VERSION "created by canmatrix"

NS_ :

BS_:

BU_: DMSCCfg

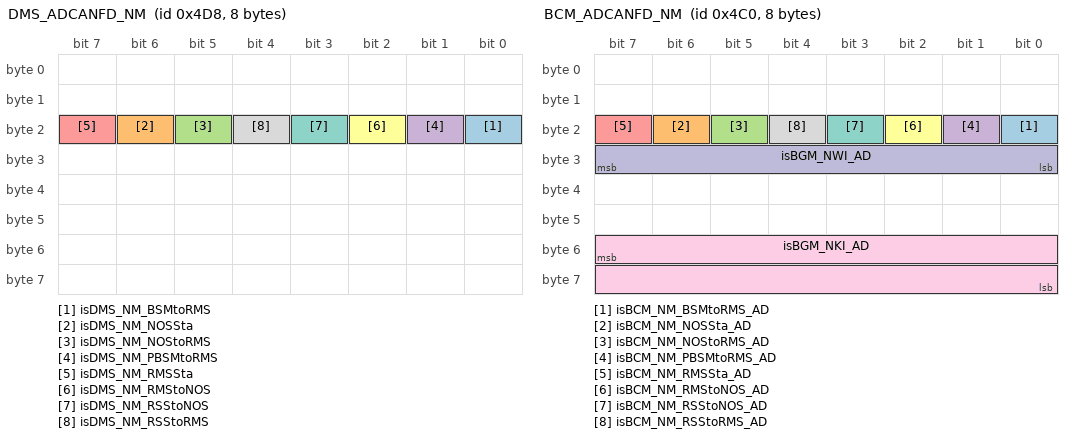
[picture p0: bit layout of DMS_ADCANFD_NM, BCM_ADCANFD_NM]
BO_ 1240 DMS_ADCANFD_NM: 8 DMSCCfg
 SG_ isDMS_NM_BSMtoRMS : 16|1@0+ (1,0) [0|1] "" Vector__XXX
 SG_ isDMS_NM_NOSSta : 22|1@0+ (1,0) [0|1] "" Vector__XXX
 SG_ isDMS_NM_NOStoRMS : 21|1@0+ (1,0) [0|1] "" Vector__XXX
 SG_ isDMS_NM_PBSMtoRMS : 17|1@0+ (1,0) [0|1] "" Vector__XXX
 SG_ isDMS_NM_RMSSta : 23|1@0+ (1,0) [0|1] "" Vector__XXX
 SG_ isDMS_NM_RMStoNOS : 18|1@0+ (1,0) [0|1] "" Vector__XXX
 SG_ isDMS_NM_RSStoNOS : 19|1@0+ (1,0) [0|1] "" Vector__XXX
 SG_ isDMS_NM_RSStoRMS : 20|1@0+ (1,0) [0|1] "" Vector__XXX

BO_ 1994 DIAG_ADCANFD_DTCInfo_DMS: 7 DMSCCfg
 SG_ isDTCInfomationDMS : 7|56@0+ (1,0) [0|7.20575940379279E+016] "" Vector__XXX

BO_ 1216 BCM_ADCANFD_NM: 8 Vector__XXX
 SG_ isBCM_NM_BSMtoRMS_AD : 16|1@0+ (1,0) [0|1] "" Vector__XXX
 SG_ isBCM_NM_NOSSta_AD : 22|1@0+ (1,0) [0|1] "" Vector__XXX
 SG_ isBCM_NM_NOStoRMS_AD : 21|1@0+ (1,0) [0|1] "" Vector__XXX
 SG_ isBCM_NM_PBSMtoRMS_AD : 17|1@0+ (1,0) [0|1] "" Vector__XXX
 SG_ isBCM_NM_RMSSta_AD : 23|1@0+ (1,0) [0|1] "" Vector__XXX
 SG_ isBCM_NM_RMStoNOS_AD : 18|1@0+ (1,0) [0|1] "" Vector__XXX
 SG_ isBCM_NM_RSStoNOS_AD : 19|1@0+ (1,0) [0|1] "" Vector__XXX
 SG_ isBCM_NM_RSStoRMS_AD : 20|1@0+ (1,0) [0|1] "" Vector__XXX
 SG_ isBGM_NKI_AD : 55|16@0+ (1,0) [0|65535] "" Vector__XXX
 SG_ isBGM_NWI_AD : 31|8@0+ (1,0) [0|255] "" Vector__XXX

BO_ 554 DMS_ADCANFD_FrP01: 64 DMSCCfg
 SG_ Header_ID M : 7|24@0- (1,0) [-8388608|8388607] "" Vector__XXX
 SG_ Header_DLC : 31|8@0- (1,0) [-128|127] "" Vector__XXX
 SG_ isDMSAdoWrnngDspCmd m18432 : 95|2@0+ (1,0) [0|3] "" Vector__XXX
 SG_ isDMSAudReq m18432 : 93|2@0+ (1,0) [0|3] "" Vector__XXX
 SG_ isDMSDspCmd m18432 : 91|2@0+ (1,0) [0|3] "" Vector__XXX
 SG_ isDMSDstrctnAdoWrnngDspCmd m18432 : 73|2@0+ (1,0) [0|3] "" Vector__XXX
 SG_ isDMSDstrctnDspCmd m18432 : 75|2@0+ (1,0) [0|3] "" Vector__XXX
 SG_ isDMSSts m18432 : 47|3@0+ (1,0) [0|7] "" Vector__XXX
 SG_ isDMSWrnngReq m18432 : 87|3@0+ (1,0) [0|7] "" Vector__XXX
 SG_ isDrvrAbnormBehvor m18432 : 79|4@0+ (1,0) [0|15] "" Vector__XXX
 SG_ isDrvrDstcnSts m18432 : 50|3@0+ (1,0) [0|7] "" Vector__XXX
 SG_ isDrvrFtgLvl m18432 : 53|3@0+ (1,0) [0|7] "" Vector__XXX
 SG_ isDrvrGazeRgn m18432 : 84|5@0+ (1,0) [0|31] "" Vector__XXX
 SG_ isDrvrPrst m18432 : 58|3@0+ (1,0) [0|7] "" Vector__XXX
 SG_ isEyeOnRoad m18432 : 61|3@0+ (1,0) [0|7] "" Vector__XXX
 SG_ isSpfngDet m18432 : 63|2@0+ (1,0) [0|3] "" Vector__XXX
 SG_ isDMSDstrctnHptWrnngDspCmd m18432 : 71|2@0+ (1,0) [0|3] "" Vector__XXX
 SG_ isDMSHapticWrnngDspCmd m18432 : 89|2@0+ (1,0) [0|3] "" Vector__XXX

BO_ 171 CCP_ADCANFD_PDUGW_FrP12: 64 Vector__XXX
 SG_ Header_ID M : 7|24@0- (1,0) [-8388608|8388607] "" Vector__XXX
 SG_ Header_DLC : 31|8@0- (1,0) [-128|127] "" Vector__XXX
 SG_ isStrgWhlAngSnsrFlt m200704 : 44|1@0+ (1,0) [0|1] ""  DMSCCfg
 SG_ isStrgWhlAngV m200704 : 45|1@0+ (1,0) [0|1] ""  DMSCCfg
 SG_ isStrgWhlAngSnsrMultCapb m200704 : 46|1@0+ (1,0) [0|1] ""  DMSCCfg
 SG_ isStrgWhlAngSnsrCalSts m200704 : 75|2@0+ (1,0) [0|3] ""  DMSCCfg
 SG_ isStrgWhlAng m200704 : 55|16@0+ (0.0625,-2048) [-2048|2047.9375] ""  DMSCCfg
 SG_ isStrgWhlAngGrd m200704 : 71|12@0+ (1,-2048) [-2048|2047] ""  DMSCCfg
 SG_ isStrgWhlAngSnsrInid m200704 : 47|1@0+ (1,0) [0|1] ""  DMSCCfg

BO_ 555 CCP_ADCANFD_PDUGW_FrP13: 64 Vector__XXX
 SG_ Header_ID M : 7|24@0- (1,0) [-8388608|8388607] "" Vector__XXX
 SG_ Header_DLC : 31|8@0- (1,0) [-128|127] "" Vector__XXX
 SG_ isSysBPM m266560 : 59|2@0+ (1,0) [0|3] ""  DMSCCfg
 SG_ isSysBPMEnbd m266560 : 57|1@0+ (1,0) [0|1] ""  DMSCCfg

BO_ 474 FVCM_ADCANFD_FrP00: 64 Vector__XXX
 SG_ Header_ID M : 7|24@0- (1,0) [-8388608|8388607] "" Vector__XXX
 SG_ Header_DLC : 31|8@0- (1,0) [-128|127] "" Vector__XXX
 SG_ isLDWLKALVsulznReq m133377 : 36|3@0+ (1,0) [0|7] ""  DMSCCfg
 SG_ isLDWLKARVsulznReq m133377 : 47|3@0+ (1,0) [0|7] ""  DMSCCfg
 SG_ isLKASysSts m133377 : 63|3@0+ (1,0) [0|7] ""  DMSCCfg

BO_ 366 FDR_ADCANFD_FrP01: 64 Vector__XXX
 SG_ Header_ID M : 7|24@0- (1,0) [-8388608|8388607] "" Vector__XXX
 SG_ Header_DLC : 31|8@0- (1,0) [-128|127] "" Vector__XXX
 SG_ isACCSysSts m144389 : 47|3@0+ (1,0) [0|7] ""  DMSCCfg

BO_ 343 FDR_ADCANFD_FrP00: 64 Vector__XXX
 SG_ Header_ID M : 7|24@0- (1,0) [-8388608|8388607] "" Vector__XXX
 SG_ Header_DLC : 31|8@0- (1,0) [-128|127] "" Vector__XXX
 SG_ isAEBSysSts m144390 : 47|3@0+ (1,0) [0|7] ""  DMSCCfg

BO_ 497 CCP_ADCANFD_FrP02: 64 Vector__XXX
 SG_ Header_ID M : 7|24@0- (1,0) [-8388608|8388607] "" Vector__XXX
 SG_ Header_DLC : 31|8@0- (1,0) [-128|127] "" Vector__XXX
 SG_ isSysOpnlMd m65538 : 47|3@0+ (1,0) [0|7] ""  DMSCCfg
 SG_ isSysPwrMd m65538 : 63|2@0+ (1,0) [0|3] ""  DMSCCfg
 SG_ isSysPwrMdV m65538 : 58|1@0+ (1,0) [0|1] ""  DMSCCfg
 SG_ isSysVol m65538 : 55|8@0+ (0.1,3) [3|28.5] ""  DMSCCfg
 SG_ isSysVolMd m65538 : 61|2@0+ (1,0) [0|3] ""  DMSCCfg
 SG_ isSysVolMdV m65538 : 44|1@0+ (1,0) [0|1] ""  DMSCCfg
 SG_ isSysVolV m65538 : 57|1@0+ (1,0) [0|1] ""  DMSCCfg
 SG_ isBrkPdlDrvrAppdPrs m209158 : 55|8@0+ (75,0) [0|19125] ""  DMSCCfg
 SG_ isBrkPdlDrvrAppdPrsV m209158 : 44|1@0+ (1,0) [0|1] ""  DMSCCfg
 SG_ isBMSAvlbly m65536 : 54|1@0+ (1,0) [0|1] ""  DMSCCfg
 SG_ isSCSAvlbly m65536 : 36|1@0+ (1,0) [0|1] ""  DMSCCfg
 SG_ isVCUAvlbly m65536 : 44|1@0+ (1,0) [0|1] ""  DMSCCfg
 SG_ isIPKAvlbly m65536 : 62|1@0+ (1,0) [0|1] ""  DMSCCfg
 SG_ isFICMAvlbly m65536 : 57|1@0+ (1,0) [0|1] ""  DMSCCfg
 SG_ isBCMAvlbly m65536 : 63|1@0+ (1,0) [0|1] ""  DMSCCfg
 SG_ isSDMAvlbly m65536 : 37|1@0+ (1,0) [0|1] ""  DMSCCfg
 SG_ isADASAvlbly m65536 : 53|1@0+ (1,0) [0|1] ""  DMSCCfg
 SG_ isEPSAvlbly m65536 : 33|1@0+ (1,0) [0|1] ""  DMSCCfg
 SG_ isTCAvlbly m65536 : 40|1@0+ (1,0) [0|1] ""  DMSCCfg
 SG_ isSASAvlbly m65536 : 47|1@0+ (1,0) [0|1] ""  DMSCCfg
 SG_ isTBOXAvlbly m65536 : 58|1@0+ (1,0) [0|1] ""  DMSCCfg
 SG_ isACAvlbly m65536 : 61|1@0+ (1,0) [0|1] ""  DMSCCfg
 SG_ isEPBAvlbly m65536 : 32|1@0+ (1,0) [0|1] ""  DMSCCfg
 SG_ isSCUAvlbly m65536 : 35|1@0+ (1,0) [0|1] ""  DMSCCfg
 SG_ isTPMSAvlbly m65536 : 68|1@0+ (1,0) [0|1] ""  DMSCCfg
 SG_ isDMSAvlbly m65536 : 50|1@0+ (1,0) [0|1] ""  DMSCCfg
 SG_ isCCUAvlbly m65536 : 87|1@0+ (1,0) [0|1] ""  DMSCCfg
 SG_ isESCLAvlbly m65536 : 86|1@0+ (1,0) [0|1] ""  DMSCCfg
 SG_ isRDAAvlbly m65536 : 67|1@0+ (1,0) [0|1] ""  DMSCCfg
 SG_ isPLCMAvlbly m65536 : 41|1@0+ (1,0) [0|1] ""  DMSCCfg
 SG_ isTDMAvlbly m65536 : 64|1@0+ (1,0) [0|1] ""  DMSCCfg
 SG_ isRCPDAvlbly m65536 : 89|1@0+ (1,0) [0|1] ""  DMSCCfg

BO_ 1142 CCP_ADCANFD_PDUGW_FrP02: 64 Vector__XXX
 SG_ Header_ID M : 7|24@0- (1,0) [-8388608|8388607] "" Vector__XXX
 SG_ Header_DLC : 31|8@0- (1,0) [-128|127] "" Vector__XXX
 SG_ isCalendarDay m338182 : 52|5@0+ (1,0) [0|31] ""  DMSCCfg
 SG_ isCalendarMonth m338182 : 47|4@0+ (1,0) [0|15] ""  DMSCCfg
 SG_ isCalendarYear m338182 : 63|8@0+ (1,2000) [2000|2255] ""  DMSCCfg
 SG_ isHourOfDay m338182 : 84|5@0+ (1,0) [0|31] ""  DMSCCfg
 SG_ isMinuteOfHour m338182 : 69|6@0+ (1,0) [0|63] ""  DMSCCfg
 SG_ isSecsOfMinute m338182 : 77|6@0+ (1,0) [0|63] ""  DMSCCfg
 SG_ isTimeDspFmt m338182 : 78|1@0+ (1,0) [0|1] ""  DMSCCfg

BO_ 451 CCP_ADCANFD_SigGW_FrP01: 64 Vector__XXX
 SG_ Header_ID M : 7|24@0- (1,0) [-8388608|8388607] "" Vector__XXX
 SG_ Header_DLC : 31|8@0- (1,0) [-128|127] "" Vector__XXX
 SG_ isClstrDspdVehSpd m1114136 : 55|8@0+ (1,0) [0|255] ""  DMSCCfg
 SG_ isDspMeasSys m1114136 : 44|1@0+ (1,0) [0|1] ""  DMSCCfg

BO_ 814 CCP_ADCANFD_FrP07: 64 Vector__XXX
 SG_ Header_ID M : 7|24@0- (1,0) [-8388608|8388607] "" Vector__XXX
 SG_ Header_DLC : 31|8@0- (1,0) [-128|127] "" Vector__XXX
 SG_ isVehPwrCsumpMd m65542 : 79|2@0+ (1,0) [0|3] ""  DMSCCfg
 SG_ isDMSAdoWrnngReq m333864 : 55|2@0+ (1,0) [0|3] ""  DMSCCfg
 SG_ isDMSHapticWrnngReq m333864 : 53|2@0+ (1,0) [0|3] ""  DMSCCfg
 SG_ isDMSSwReq m333864 : 51|2@0+ (1,0) [0|3] ""  DMSCCfg
 SG_ isFOTASts m9473 : 47|1@0+ (1,0) [0|1] ""  DMSCCfg
 SG_ isFOTAStsV m9473 : 55|1@0+ (1,0) [0|1] ""  DMSCCfg
 SG_ isLDircnIndLghtF m1114113 : 47|1@0+ (1,0) [0|1] ""  DMSCCfg
 SG_ isRDircnIndLghtF m1114113 : 43|1@0+ (1,0) [0|1] ""  DMSCCfg
 SG_ isDircnIndLampSwSts m1114113 : 55|2@0+ (1,0) [0|3] ""  DMSCCfg
 SG_ isRstrFctryDeftsReq m1114113 : 46|1@0+ (1,0) [0|1] ""  DMSCCfg

BO_ 812 CCP_ADCANFD_PDUGW_FrP04: 64 Vector__XXX
 SG_ Header_ID M : 7|24@0- (1,0) [-8388608|8388607] "" Vector__XXX
 SG_ Header_DLC : 31|8@0- (1,0) [-128|127] "" Vector__XXX
 SG_ isDrvrDoorOpenSts m266500 : 47|2@0+ (1,0) [0|3] ""  DMSCCfg

BO_ 165 CCP_ADCANFD_PDUGW_FrP19: 64 Vector__XXX
 SG_ Header_ID M : 7|24@0- (1,0) [-8388608|8388607] "" Vector__XXX
 SG_ Header_DLC : 31|8@0- (1,0) [-128|127] "" Vector__XXX
 SG_ isBrkPdlAppd m132626 : 67|1@0+ (1,0) [0|1] ""  DMSCCfg
 SG_ isBrkPdlAppdV m132626 : 47|2@0+ (1,0) [0|3] ""  DMSCCfg
 SG_ isDrvrReqOtptRodTrvl m132626 : 63|12@0+ (0.015625,-5) [-5|58.984375] ""  DMSCCfg
 SG_ isDrvrReqOtptRodTrvlSts m132626 : 45|2@0+ (1,0) [0|3] ""  DMSCCfg

BO_ 318 CCP_ADCANFD_PDUGW_FrP03: 64 Vector__XXX
 SG_ Header_ID M : 7|24@0- (1,0) [-8388608|8388607] "" Vector__XXX
 SG_ Header_DLC : 31|8@0- (1,0) [-128|127] "" Vector__XXX
 SG_ isVehSpdAvg m209173 : 54|15@0+ (0.015625,0) [0|511.984375] ""  DMSCCfg
 SG_ isVehSpdAvgDrvn m209173 : 71|15@0+ (0.015625,0) [0|511.984375] ""  DMSCCfg
 SG_ isVehSpdAvgDrvnV m209173 : 72|1@0+ (1,0) [0|1] ""  DMSCCfg
 SG_ isVehSpdAvgNonDrvn m209173 : 86|15@0+ (0.015625,0) [0|511.984375] ""  DMSCCfg
 SG_ isVehSpdAvgNonDrvnV m209173 : 47|1@0+ (1,0) [0|1] ""  DMSCCfg
 SG_ isVehSpdAvgV m209173 : 55|1@0+ (1,0) [0|1] ""  DMSCCfg
 SG_ isDrvrSbltAtc m132864 : 55|1@0+ (1,0) [0|1] ""  DMSCCfg
 SG_ isDrvrSbltAtcV m132864 : 54|1@0+ (1,0) [0|1] ""  DMSCCfg

BO_ 70 CCP_ADCANFD_PDUGW_FrP31: 64 Vector__XXX
 SG_ Header_ID M : 7|24@0- (1,0) [-8388608|8388607] "" Vector__XXX
 SG_ Header_DLC : 31|8@0- (1,0) [-128|127] "" Vector__XXX
 SG_ isEPTAccelActuPos m256 : 55|8@0+ (0.392157,0) [0|100.000035] ""  DMSCCfg
 SG_ isEPTAccelActuPosV m256 : 63|1@0+ (1,0) [0|1] ""  DMSCCfg
 SG_ isEPTBrkPdlDscrtInptStsV m256 : 44|1@0+ (1,0) [0|1] ""  DMSCCfg
 SG_ isEPTBrkPdlDscrtInptSts m256 : 45|1@0+ (1,0) [0|1] ""  DMSCCfg
 SG_ isEPTRdy m256 : 70|1@0+ (1,0) [0|1] ""  DMSCCfg
 SG_ isEPTStCmdOn m256 : 67|1@0+ (1,0) [0|1] ""  DMSCCfg

BO_ 404 CCP_ADCANFD_PDUGW_FrP10: 64 Vector__XXX
 SG_ Header_ID M : 7|24@0- (1,0) [-8388608|8388607] "" Vector__XXX
 SG_ Header_DLC : 31|8@0- (1,0) [-128|127] "" Vector__XXX
 SG_ isTrShftLvrPosV m272 : 60|1@0+ (1,0) [0|1] ""  DMSCCfg
 SG_ isTrShftLvrPos m272 : 59|4@0+ (1,0) [0|15] ""  DMSCCfg

BO_ 319 CCP_ADCANFD_PDUGW_FrP06: 64 Vector__XXX
 SG_ Header_ID M : 7|24@0- (1,0) [-8388608|8388607] "" Vector__XXX
 SG_ Header_DLC : 31|8@0- (1,0) [-128|127] "" Vector__XXX
 SG_ isVehDynYawRateV m209160 : 46|1@0+ (1,0) [0|1] ""  DMSCCfg
 SG_ isVehDynYawRate m209160 : 59|12@0- (0.0625,0) [-128|127.9375] ""  DMSCCfg
 SG_ isVSELatAcc m209160 : 55|12@0- (0.015625,0) [-32|31.984375] ""  DMSCCfg
 SG_ isVSELatAccV m209160 : 47|1@0+ (1,0) [0|1] ""  DMSCCfg
 SG_ isVSELongtAcc m209160 : 79|10@0- (0.03,0) [-15.36|15.33] ""  DMSCCfg
 SG_ isVSELongtAccV m209160 : 45|1@0+ (1,0) [0|1] ""  DMSCCfg

BO_ 1352 CCP_ADCANFD_PDUGW_FrP09: 64 Vector__XXX
 SG_ Header_ID M : 7|24@0- (1,0) [-8388608|8388607] "" Vector__XXX
 SG_ Header_DLC : 31|8@0- (1,0) [-128|127] "" Vector__XXX
 SG_ isVehOdo m65556 : 55|24@0+ (1,0) [0|16777215] ""  DMSCCfg
 SG_ isVehOdoV m65556 : 92|1@0+ (1,0) [0|1] ""  DMSCCfg

BO_ 924 CCP_ADCANFD_SigGW_FrP24: 64 Vector__XXX
 SG_ Header_ID M : 7|24@0- (1,0) [-8388608|8388607] "" Vector__XXX
 SG_ Header_DLC : 31|8@0- (1,0) [-128|127] "" Vector__XXX
 SG_ isDMSDstrctnAdoWrnngReq m337974 : 37|2@0+ (1,0) [0|3] ""  DMSCCfg
 SG_ isDMSDstrctnHptWrnngReq m337974 : 35|2@0+ (1,0) [0|3] ""  DMSCCfg
 SG_ isDMSDstrctnSwReq m337974 : 39|2@0+ (1,0) [0|3] ""  DMSCCfg

BO_ 192 CCP_ADCANFD_SigGW_FrP00: 64 Vector__XXX
 SG_ Header_ID M : 7|24@0- (1,0) [-8388608|8388607] "" Vector__XXX
 SG_ Header_DLC : 31|8@0- (1,0) [-128|127] "" Vector__XXX
 SG_ isDrvrStrgDlvrdToq m4103 : 55|11@0+ (0.01,-10.24) [-10.24|10.23] ""  DMSCCfg
 SG_ isDrvrStrgDlvrdToqV m4103 : 44|1@0+ (1,0) [0|1] ""  DMSCCfg
 SG_ isLDircnIO m1114135 : 39|1@0+ (1,0) [0|1] ""  DMSCCfg
 SG_ isRDircnIO m1114135 : 38|1@0+ (1,0) [0|1] ""  DMSCCfg

BO_ 302 CCP_ADCANFD_PDUGW_FrP38: 64 Vector__XXX
 SG_ Header_ID M : 7|24@0- (1,0) [-8388608|8388607] "" Vector__XXX
 SG_ Header_DLC : 31|8@0- (1,0) [-128|127] "" Vector__XXX
 SG_ isVSELatAccV_SDM m132872 : 47|1@0+ (1,0) [0|1] ""  DMSCCfg
 SG_ isVehDynYawRate_SDM m132872 : 59|12@0- (0.0625,0) [-128|127.9375] ""  DMSCCfg
 SG_ isVSELongtAccV_SDM m132872 : 45|1@0+ (1,0) [0|1] ""  DMSCCfg
 SG_ isVSELongtAcc_SDM m132872 : 79|10@0- (0.03,0) [-15.36|15.33] ""  DMSCCfg
 SG_ isVSELatAcc_SDM m132872 : 55|12@0- (0.015625,0) [-32|31.984375] ""  DMSCCfg
 SG_ isVehDynYawRateV_SDM m132872 : 46|1@0+ (1,0) [0|1] ""  DMSCCfg

CM_ SG_ 1216 isBGM_NKI_AD "Body Control Module And Gateway Network Keep Indication";
CM_ SG_ 1216 isBGM_NWI_AD "Body Control Module And Gateway Network Wakeup Indication";
CM_ SG_ 554 isDMSAdoWrnngDspCmd "Driver Monitor System Audio Warning Display Command";
CM_ SG_ 554 isDMSAudReq "Driver Monitor System Audible Request";
CM_ SG_ 554 isDMSDspCmd "Driver Monitor System Display Command";
CM_ SG_ 554 isDMSDstrctnAdoWrnngDspCmd "Driver Monitor System Distraction Audio Warning Display Command";
CM_ SG_ 554 isDMSDstrctnDspCmd "Driver Monitor System Distraction Display Command";
CM_ SG_ 554 isDMSSts "Driver Monitor System Status";
CM_ SG_ 554 isDMSWrnngReq "Driver Monitor System Warning Request";
CM_ SG_ 554 isDrvrAbnormBehvor "Driver Abnormal Behaviour";
CM_ SG_ 554 isDrvrDstcnSts "Driver Distraction Status";
CM_ SG_ 554 isDrvrFtgLvl "Driver Fatigue Level";
CM_ SG_ 554 isDrvrGazeRgn "Driver Gaze Region";
CM_ SG_ 554 isDrvrPrst "Driver Present";
CM_ SG_ 554 isEyeOnRoad "Eye On Road";
CM_ SG_ 554 isSpfngDet "Spoofing Detected";
CM_ SG_ 554 isDMSDstrctnHptWrnngDspCmd "Driver Monitor System Distraction Haptic Warning Display Command";
CM_ SG_ 554 isDMSHapticWrnngDspCmd "Driver Monitor System Haptic Warning Display Command";
CM_ SG_ 171 isStrgWhlAngSnsrFlt "Steering Wheel Angle Sensor Fault";
CM_ SG_ 171 isStrgWhlAngV "Steering Wheel Angle Validity";
CM_ SG_ 171 isStrgWhlAngSnsrMultCapb "Steering Wheel Angle Sensor Multiturn Capable";
CM_ SG_ 171 isStrgWhlAngSnsrCalSts "Steering Wheel Angle Sensor Calibration Status";
CM_ SG_ 171 isStrgWhlAng "Steering Wheel Angle";
CM_ SG_ 171 isStrgWhlAngGrd "Steering Wheel Angle Gradient";
CM_ SG_ 171 isStrgWhlAngSnsrInid "Steering Wheel Angle Sensor Initialized";
CM_ SG_ 555 isSysBPM "System Backup Power Mode";
CM_ SG_ 555 isSysBPMEnbd "System Backup Power Mode Enabled";
CM_ SG_ 474 isLDWLKALVsulznReq "Lane Departure Warning Lane Keeping Assist Left Visualization Request";
CM_ SG_ 474 isLDWLKARVsulznReq "Lane Departure Warning Lane Keeping Assist Right Visualization Request";
CM_ SG_ 474 isLKASysSts "Lane Keeping Assist System Status";
CM_ SG_ 366 isACCSysSts "Adaptive Cruise Control System Status";
CM_ SG_ 343 isAEBSysSts "Autonomous Emergency Braking System Status";
CM_ SG_ 497 isSysOpnlMd "System Operational Mode";
CM_ SG_ 497 isSysPwrMd "System Power Mode";
CM_ SG_ 497 isSysPwrMdV "System Power Mode Validity";
CM_ SG_ 497 isSysVol "System Voltage";
CM_ SG_ 497 isSysVolMd "System Voltage Mode";
CM_ SG_ 497 isSysVolMdV "System Voltage Mode Validity";
CM_ SG_ 497 isSysVolV "System Voltage Validity";
CM_ SG_ 497 isBrkPdlDrvrAppdPrs "Brake Pedal Driver Applied Pressure";
CM_ SG_ 497 isBrkPdlDrvrAppdPrsV "Brake Pedal Driver Applied Pressure Validity";
CM_ SG_ 497 isBMSAvlbly "Battery Management System Availability";
CM_ SG_ 497 isSCSAvlbly "Stability Control System Availability";
CM_ SG_ 497 isVCUAvlbly "Vehicle Control Unit Availability";
CM_ SG_ 497 isFICMAvlbly "Front Infotainment Control Module Availability";
CM_ SG_ 497 isBCMAvlbly "Body Control Module Availability";
CM_ SG_ 497 isSDMAvlbly "Sensing Diagnostic Module Availability";
CM_ SG_ 497 isADASAvlbly "Advanced Driver Assistance System Availability";
CM_ SG_ 497 isEPSAvlbly "Electric Power Steering Availability";
CM_ SG_ 497 isACAvlbly "Air Conditioning Availability";
CM_ SG_ 497 isEPBAvlbly "Electric Park Brake Availability";
CM_ SG_ 497 isSCUAvlbly "Shifter Control Unit Availability";
CM_ SG_ 497 isTPMSAvlbly "Tire Pressure Monitor System Availability";
CM_ SG_ 497 isDMSAvlbly "Driver Monitor System Availability";
CM_ SG_ 497 isCCUAvlbly "Combined Charging Unit Availability";
CM_ SG_ 497 isESCLAvlbly "Electronic Steering Column Lock Availability";
CM_ SG_ 497 isRCPDAvlbly "Air Conditioning Availability";
CM_ SG_ 1142 isCalendarDay "Calendar Day";
CM_ SG_ 1142 isCalendarMonth "Calendar Month";
CM_ SG_ 1142 isCalendarYear "Calendar Year";
CM_ SG_ 1142 isHourOfDay "Hour Of Day";
CM_ SG_ 1142 isMinuteOfHour "Minute Of Hour";
CM_ SG_ 1142 isSecsOfMinute "Seconds Of Minute";
CM_ SG_ 1142 isTimeDspFmt "Time Display Format";
CM_ SG_ 451 isClstrDspdVehSpd "Cluster Displayed Vehicle Speed";
CM_ SG_ 451 isDspMeasSys "Display Measurement System";
CM_ SG_ 814 isVehPwrCsumpMd "Vehicle Power Consumption Mode";
CM_ SG_ 814 isDMSAdoWrnngReq "Driver Monitor System Audio Warning Request";
CM_ SG_ 814 isDMSHapticWrnngReq "Driver Monitor System Haptic Warning Request";
CM_ SG_ 814 isDMSSwReq "Driver Monitor System Switch Request";
CM_ SG_ 814 isFOTASts "Firmware Over The Air Status";
CM_ SG_ 814 isFOTAStsV "Firmware Over The Air Status Validity";
CM_ SG_ 814 isLDircnIndLghtF "Left Direction Indication Light Failed";
CM_ SG_ 814 isRDircnIndLghtF "Right Direction Indication Light Failed";
CM_ SG_ 814 isDircnIndLampSwSts "Direction Indication Lamp Switch Status";
CM_ SG_ 814 isRstrFctryDeftsReq "Restore Factory Defaults Request";
CM_ SG_ 812 isDrvrDoorOpenSts "Driver Door Open Status";
CM_ SG_ 165 isBrkPdlAppd "Brake Pedal Applied";
CM_ SG_ 165 isBrkPdlAppdV "Brake Pedal Applied Validity";
CM_ SG_ 165 isDrvrReqOtptRodTrvl "Driver Request Output Rod Travel";
CM_ SG_ 165 isDrvrReqOtptRodTrvlSts "Driver Request Output Rod Travel Status";
CM_ SG_ 318 isVehSpdAvg "Vehicle Speed Average";
CM_ SG_ 318 isVehSpdAvgDrvn "Vehicle Speed Average Driven";
CM_ SG_ 318 isVehSpdAvgDrvnV "Vehicle Speed Average Driven Validity";
CM_ SG_ 318 isVehSpdAvgNonDrvn "Vehicle Speed Average Non Driven";
CM_ SG_ 318 isVehSpdAvgNonDrvnV "Vehicle Speed Average Non Driven Validity";
CM_ SG_ 318 isVehSpdAvgV "Vehicle Speed Average Validity";
CM_ SG_ 318 isDrvrSbltAtc "Driver Seatbelt Attached";
CM_ SG_ 318 isDrvrSbltAtcV "Driver Seatbelt Attached Validity";
CM_ SG_ 70 isEPTAccelActuPos "Electric Powertrain Accelerator Actual Position";
CM_ SG_ 70 isEPTAccelActuPosV "Electric Powertrain Accelerator Actual Position Validity";
CM_ SG_ 70 isEPTBrkPdlDscrtInptStsV "Electric Powertrain Brake Pedal Discrete Input Status Validity";
CM_ SG_ 70 isEPTBrkPdlDscrtInptSts "Electric Powertrain Brake Pedal Discrete Input Status";
CM_ SG_ 70 isEPTRdy "Electric Powertrain Ready";
CM_ SG_ 70 isEPTStCmdOn "Electric Powertrain Start Command On";
CM_ SG_ 404 isTrShftLvrPosV "Transmission Shift Lever Position Validity";
CM_ SG_ 404 isTrShftLvrPos "Transmission Shift Lever Position";
CM_ SG_ 319 isVehDynYawRateV "Vehicle Dynamics Yaw Rate Validity";
CM_ SG_ 319 isVehDynYawRate "Vehicle Dynamics Yaw Rate";
CM_ SG_ 319 isVSELatAcc "Vehicle Stability Enhancement Lateral Acceleration";
CM_ SG_ 319 isVSELatAccV "Vehicle Stability Enhancement Lateral Acceleration Validity";
CM_ SG_ 319 isVSELongtAcc "Vehicle Stability Enhancement Longitudinal Acceleration";
CM_ SG_ 319 isVSELongtAccV "Vehicle Stability Enhancement Longitudinal Acceleration Validity";
CM_ SG_ 1352 isVehOdo "Vehicle Odometer";
CM_ SG_ 1352 isVehOdoV "Vehicle Odometer Validity";
CM_ SG_ 924 isDMSDstrctnAdoWrnngReq "Driver Monitor System Distraction Audio Warning Request";
CM_ SG_ 924 isDMSDstrctnHptWrnngReq "Driver Monitor System Distraction Haptic Warning Request";
CM_ SG_ 924 isDMSDstrctnSwReq "Driver Monitor System Distraction Switch Request";
CM_ SG_ 192 isDrvrStrgDlvrdToq "Driver Steering Delivered Torque";
CM_ SG_ 192 isDrvrStrgDlvrdToqV "Driver Steering Delivered Torque Validity";
CM_ SG_ 192 isLDircnIO "Left Direction Indication On";
CM_ SG_ 192 isRDircnIO "Right Direction Indication On";
CM_ SG_ 302 isVehDynYawRate_SDM "Vehicle Dynamics Yaw Rate_sdm";
CM_ SG_ 302 isVSELongtAccV_SDM "Vehicle Stability Enhancement Longitudinal Acceleration Validity_sdm";
CM_ SG_ 302 isVSELongtAcc_SDM "Vehicle Stability Enhancement Longitudinal Acceleration_sdm";
CM_ SG_ 302 isVSELatAcc_SDM "Vehicle Stability Enhancement Lateral Acceleration_sdm";
CM_ SG_ 302 isVehDynYawRateV_SDM "Vehicle Dynamics Yaw Rate Validity_sdm";
BA_DEF_ BO_  "FrameTriggeringName" STRING ;
BA_DEF_ BO_  "GenMsgCycleTime" INT 0 65535;
BA_DEF_ BO_  "GenMsgSendType" ENUM  "cyclicX","spontanX","cyclicIfActiveX","spontanWithDelay","cyclicAndSpontanX","cyclicAndSpontanWithDelay","spontanWithRepitition","cyclicIfActiveAndSpontanWD","cyclicIfActiveFast","cyclicWithRepeatOnDemand","none";
BA_DEF_ BO_  "GenMsgStartValue" STRING ;
BA_DEF_ BO_  "PduName" STRING ;
BA_DEF_ BO_  "VFrameFormat" ENUM  "StandardCAN","ExtendedCAN","reserved","reserved","reserved","reserved","reserved","reserved","reserved","reserved","reserved","reserved","reserved","reserved","StandardCAN_FD","ExtendedCAN_FD";
BA_DEF_ SG_  "CompuMethodName" STRING ;
BA_DEF_ SG_  "ISignalName" STRING ;
BA_DEF_ SG_  "SysSignalName" STRING ;
BA_DEF_ BU_  "NWM-Knoten" ENUM  "nein","ja";
BA_DEF_ BU_  "NWM-Stationsadresse" HEX 0 63;
BA_DEF_  "BusType" STRING ;
BA_DEF_DEF_  "FrameTriggeringName" "";
BA_DEF_DEF_  "GenMsgCycleTime" 0;
BA_DEF_DEF_  "GenMsgSendType" "";
BA_DEF_DEF_  "GenMsgStartValue" "";
BA_DEF_DEF_  "PduName" "";
BA_DEF_DEF_  "VFrameFormat" "";
BA_DEF_DEF_  "CompuMethodName" "";
BA_DEF_DEF_  "ISignalName" "";
BA_DEF_DEF_  "SysSignalName" "";
BA_DEF_DEF_  "NWM-Knoten" "";
BA_DEF_DEF_  "NWM-Stationsadresse" 0;
BA_DEF_DEF_  "BusType" "";
BA_ "BusType" "CAN FD";
BA_ "NWM-Knoten" BU_ DMSCCfg 0;
BA_ "PduName" BO_ 1240 "NmPDU_ADCANFD_DMS";
BA_ "GenMsgStartValue" BO_ 1240 "0000000000000000";
BA_ "GenMsgSendType" BO_ 1240 1;
BA_ "FrameTriggeringName" BO_ 1240 "FrTrDMS_ADCANFD_NM";
BA_ "VFrameFormat" BO_ 1240 14;
BA_ "PduName" BO_ 1994 "DIAG_DTCInfo_DMS";
BA_ "GenMsgStartValue" BO_ 1994 "00000000000000";
BA_ "GenMsgSendType" BO_ 1994 1;
BA_ "FrameTriggeringName" BO_ 1994 "FrTrDIAG_ADCANFD_DTCInfo_DMS";
BA_ "VFrameFormat" BO_ 1994 14;
BA_ "PduName" BO_ 1216 "NmPDU_ADCANFD_BCM";
BA_ "GenMsgStartValue" BO_ 1216 "0000000000000000";
BA_ "GenMsgSendType" BO_ 1216 1;
BA_ "FrameTriggeringName" BO_ 1216 "FrTrBCM_ADCANFD_NM";
BA_ "VFrameFormat" BO_ 1216 14;
BA_ "PduName" BO_ 554 "DMS_ADCANFD_050ms_Container01";
BA_ "GenMsgSendType" BO_ 554 1;
BA_ "GenMsgCycleTime" BO_ 554 50;
BA_ "FrameTriggeringName" BO_ 554 "FrTrDMS_ADCANFD_FrP01";
BA_ "VFrameFormat" BO_ 554 14;
BA_ "PduName" BO_ 171 "CCP_ADCANFD_010ms_Container12";
BA_ "GenMsgSendType" BO_ 171 1;
BA_ "FrameTriggeringName" BO_ 171 "FrTrCCP_ADCANFD_PDUGW_FrP12";
BA_ "VFrameFormat" BO_ 171 14;
BA_ "PduName" BO_ 555 "CCP_ADCANFD_050ms_Container13";
BA_ "GenMsgSendType" BO_ 555 1;
BA_ "FrameTriggeringName" BO_ 555 "FrTrCCP_ADCANFD_PDUGW_FrP13";
BA_ "VFrameFormat" BO_ 555 14;
BA_ "PduName" BO_ 474 "FVCM_ADCANFD_020ms_Container00";
BA_ "GenMsgSendType" BO_ 474 1;
BA_ "FrameTriggeringName" BO_ 474 "FrTrFVCM_ADCANFD_FrP00";
BA_ "VFrameFormat" BO_ 474 14;
BA_ "PduName" BO_ 366 "FDR_ADCANFD_020ms_Container01";
BA_ "GenMsgSendType" BO_ 366 1;
BA_ "FrameTriggeringName" BO_ 366 "FrTrFDR_ADCANFD_FrP01";
BA_ "VFrameFormat" BO_ 366 14;
BA_ "PduName" BO_ 343 "FDR_ADCANFD_020ms_Container00";
BA_ "GenMsgSendType" BO_ 343 1;
BA_ "FrameTriggeringName" BO_ 343 "FrTrFDR_ADCANFD_FrP00";
BA_ "VFrameFormat" BO_ 343 14;
BA_ "PduName" BO_ 497 "CCP_ADCANFD_020ms_Container11";
BA_ "GenMsgSendType" BO_ 497 1;
BA_ "FrameTriggeringName" BO_ 497 "FrTrCCP_ADCANFD_FrP02";
BA_ "VFrameFormat" BO_ 497 14;
BA_ "PduName" BO_ 1142 "CCP_ADCANFD_200ms_Container02";
BA_ "GenMsgSendType" BO_ 1142 1;
BA_ "FrameTriggeringName" BO_ 1142 "FrTrCCP_ADCANFD_PDUGW_FrP02";
BA_ "VFrameFormat" BO_ 1142 14;
BA_ "PduName" BO_ 451 "CCP_ADCANFD_025ms_Container02";
BA_ "GenMsgSendType" BO_ 451 1;
BA_ "FrameTriggeringName" BO_ 451 "FrTrCCP_ADCANFD_SigGW_FrP01";
BA_ "VFrameFormat" BO_ 451 14;
BA_ "PduName" BO_ 814 "CCP_ADCANFD_100ms_Container07";
BA_ "GenMsgSendType" BO_ 814 1;
BA_ "FrameTriggeringName" BO_ 814 "FrTrCCP_ADCANFD_FrP07";
BA_ "VFrameFormat" BO_ 814 14;
BA_ "PduName" BO_ 812 "CCP_ADCANFD_100ms_Container01";
BA_ "GenMsgSendType" BO_ 812 1;
BA_ "FrameTriggeringName" BO_ 812 "FrTrCCP_ADCANFD_PDUGW_FrP04";
BA_ "VFrameFormat" BO_ 812 14;
BA_ "PduName" BO_ 165 "CCP_ADCANFD_010ms_Container19";
BA_ "GenMsgSendType" BO_ 165 1;
BA_ "FrameTriggeringName" BO_ 165 "FrTrCCP_ADCANFD_PDUGW_FrP19";
BA_ "VFrameFormat" BO_ 165 14;
BA_ "PduName" BO_ 318 "CCP_ADCANFD_020ms_Container03";
BA_ "GenMsgSendType" BO_ 318 1;
BA_ "FrameTriggeringName" BO_ 318 "FrTrCCP_ADCANFD_PDUGW_FrP03";
BA_ "VFrameFormat" BO_ 318 14;
BA_ "PduName" BO_ 70 "CCP_ADCANFD_010ms_Container31";
BA_ "GenMsgSendType" BO_ 70 1;
BA_ "FrameTriggeringName" BO_ 70 "FrTrCCP_ADCANFD_PDUGW_FrP31";
BA_ "VFrameFormat" BO_ 70 14;
BA_ "PduName" BO_ 404 "CCP_ADCANFD_020ms_Container10";
BA_ "GenMsgSendType" BO_ 404 1;
BA_ "FrameTriggeringName" BO_ 404 "FrTrCCP_ADCANFD_PDUGW_FrP10";
BA_ "VFrameFormat" BO_ 404 14;
BA_ "PduName" BO_ 319 "CCP_ADCANFD_020ms_Container06";
BA_ "GenMsgSendType" BO_ 319 1;
BA_ "FrameTriggeringName" BO_ 319 "FrTrCCP_ADCANFD_PDUGW_FrP06";
BA_ "VFrameFormat" BO_ 319 14;
BA_ "PduName" BO_ 1352 "CCP_ADCANFD_1000ms_Container09";
BA_ "GenMsgSendType" BO_ 1352 1;
BA_ "FrameTriggeringName" BO_ 1352 "FrTrCCP_ADCANFD_PDUGW_FrP09";
BA_ "VFrameFormat" BO_ 1352 14;
BA_ "PduName" BO_ 924 "CCP_ADCANFD_100ms_Container24";
BA_ "GenMsgSendType" BO_ 924 1;
BA_ "FrameTriggeringName" BO_ 924 "FrTrCCP_ADCANFD_SigGW_FrP24";
BA_ "VFrameFormat" BO_ 924 14;
BA_ "PduName" BO_ 192 "CCP_ADCANFD_010ms_Container00";
BA_ "GenMsgSendType" BO_ 192 1;
BA_ "FrameTriggeringName" BO_ 192 "FrTrCCP_ADCANFD_SigGW_FrP00";
BA_ "VFrameFormat" BO_ 192 14;
BA_ "PduName" BO_ 302 "CCP_ADCANFD_020ms_Container38";
BA_ "GenMsgSendType" BO_ 302 1;
BA_ "FrameTriggeringName" BO_ 302 "FrTrCCP_ADCANFD_PDUGW_FrP38";
BA_ "VFrameFormat" BO_ 302 14;
BA_ "SysSignalName" SG_ 1240 isDMS_NM_BSMtoRMS "DMS_NM_BSMtoRMS";
BA_ "ISignalName" SG_ 1240 isDMS_NM_BSMtoRMS "isDMS_NM_BSMtoRMS";
BA_ "CompuMethodName" SG_ 1240 isDMS_NM_BSMtoRMS "BooleanCoding";
BA_ "SysSignalName" SG_ 1240 isDMS_NM_NOSSta "DMS_NM_NOSSta";
BA_ "ISignalName" SG_ 1240 isDMS_NM_NOSSta "isDMS_NM_NOSSta";
BA_ "CompuMethodName" SG_ 1240 isDMS_NM_NOSSta "BooleanCoding";
BA_ "SysSignalName" SG_ 1240 isDMS_NM_NOStoRMS "DMS_NM_NOStoRMS";
BA_ "ISignalName" SG_ 1240 isDMS_NM_NOStoRMS "isDMS_NM_NOStoRMS";
BA_ "CompuMethodName" SG_ 1240 isDMS_NM_NOStoRMS "BooleanCoding";
BA_ "SysSignalName" SG_ 1240 isDMS_NM_PBSMtoRMS "DMS_NM_PBSMtoRMS";
BA_ "ISignalName" SG_ 1240 isDMS_NM_PBSMtoRMS "isDMS_NM_PBSMtoRMS";
BA_ "CompuMethodName" SG_ 1240 isDMS_NM_PBSMtoRMS "BooleanCoding";
BA_ "SysSignalName" SG_ 1240 isDMS_NM_RMSSta "DMS_NM_RMSSta";
BA_ "ISignalName" SG_ 1240 isDMS_NM_RMSSta "isDMS_NM_RMSSta";
BA_ "CompuMethodName" SG_ 1240 isDMS_NM_RMSSta "BooleanCoding";
BA_ "SysSignalName" SG_ 1240 isDMS_NM_RMStoNOS "DMS_NM_RMStoNOS";
BA_ "ISignalName" SG_ 1240 isDMS_NM_RMStoNOS "isDMS_NM_RMStoNOS";
BA_ "CompuMethodName" SG_ 1240 isDMS_NM_RMStoNOS "BooleanCoding";
BA_ "SysSignalName" SG_ 1240 isDMS_NM_RSStoNOS "DMS_NM_RSStoNOS";
BA_ "ISignalName" SG_ 1240 isDMS_NM_RSStoNOS "isDMS_NM_RSStoNOS";
BA_ "CompuMethodName" SG_ 1240 isDMS_NM_RSStoNOS "BooleanCoding";
BA_ "SysSignalName" SG_ 1240 isDMS_NM_RSStoRMS "DMS_NM_RSStoRMS";
BA_ "ISignalName" SG_ 1240 isDMS_NM_RSStoRMS "isDMS_NM_RSStoRMS";
BA_ "CompuMethodName" SG_ 1240 isDMS_NM_RSStoRMS "BooleanCoding";
BA_ "SysSignalName" SG_ 1994 isDTCInfomationDMS "DTCInfomationDMS";
BA_ "ISignalName" SG_ 1994 isDTCInfomationDMS "isDTCInfomationDMS";
BA_ "CompuMethodName" SG_ 1994 isDTCInfomationDMS "UnknownCM";
BA_ "SysSignalName" SG_ 1216 isBCM_NM_BSMtoRMS_AD "BCM_NM_BSMtoRMS_AD";
BA_ "ISignalName" SG_ 1216 isBCM_NM_BSMtoRMS_AD "isBCM_NM_BSMtoRMS_AD";
BA_ "CompuMethodName" SG_ 1216 isBCM_NM_BSMtoRMS_AD "BooleanCoding";
BA_ "SysSignalName" SG_ 1216 isBCM_NM_NOSSta_AD "BCM_NM_NOSSta_AD";
BA_ "ISignalName" SG_ 1216 isBCM_NM_NOSSta_AD "isBCM_NM_NOSSta_AD";
BA_ "CompuMethodName" SG_ 1216 isBCM_NM_NOSSta_AD "BooleanCoding";
BA_ "SysSignalName" SG_ 1216 isBCM_NM_NOStoRMS_AD "BCM_NM_NOStoRMS_AD";
BA_ "ISignalName" SG_ 1216 isBCM_NM_NOStoRMS_AD "isBCM_NM_NOStoRMS_AD";
BA_ "CompuMethodName" SG_ 1216 isBCM_NM_NOStoRMS_AD "BooleanCoding";
BA_ "SysSignalName" SG_ 1216 isBCM_NM_PBSMtoRMS_AD "BCM_NM_PBSMtoRMS_AD";
BA_ "ISignalName" SG_ 1216 isBCM_NM_PBSMtoRMS_AD "isBCM_NM_PBSMtoRMS_AD";
BA_ "CompuMethodName" SG_ 1216 isBCM_NM_PBSMtoRMS_AD "BooleanCoding";
BA_ "SysSignalName" SG_ 1216 isBCM_NM_RMSSta_AD "BCM_NM_RMSSta_AD";
BA_ "ISignalName" SG_ 1216 isBCM_NM_RMSSta_AD "isBCM_NM_RMSSta_AD";
BA_ "CompuMethodName" SG_ 1216 isBCM_NM_RMSSta_AD "BooleanCoding";
BA_ "SysSignalName" SG_ 1216 isBCM_NM_RMStoNOS_AD "BCM_NM_RMStoNOS_AD";
BA_ "ISignalName" SG_ 1216 isBCM_NM_RMStoNOS_AD "isBCM_NM_RMStoNOS_AD";
BA_ "CompuMethodName" SG_ 1216 isBCM_NM_RMStoNOS_AD "BooleanCoding";
BA_ "SysSignalName" SG_ 1216 isBCM_NM_RSStoNOS_AD "BCM_NM_RSStoNOS_AD";
BA_ "ISignalName" SG_ 1216 isBCM_NM_RSStoNOS_AD "isBCM_NM_RSStoNOS_AD";
BA_ "CompuMethodName" SG_ 1216 isBCM_NM_RSStoNOS_AD "BooleanCoding";
BA_ "SysSignalName" SG_ 1216 isBCM_NM_RSStoRMS_AD "BCM_NM_RSStoRMS_AD";
BA_ "ISignalName" SG_ 1216 isBCM_NM_RSStoRMS_AD "isBCM_NM_RSStoRMS_AD";
BA_ "CompuMethodName" SG_ 1216 isBCM_NM_RSStoRMS_AD "BooleanCoding";
BA_ "SysSignalName" SG_ 1216 isBGM_NKI_AD "BGM_NKI_AD";
BA_ "ISignalName" SG_ 1216 isBGM_NKI_AD "isBGM_NKI_AD";
BA_ "CompuMethodName" SG_ 1216 isBGM_NKI_AD "BGM_NKI";
BA_ "SysSignalName" SG_ 1216 isBGM_NWI_AD "BGM_NWI_AD";
BA_ "ISignalName" SG_ 1216 isBGM_NWI_AD "isBGM_NWI_AD";
BA_ "CompuMethodName" SG_ 1216 isBGM_NWI_AD "BGM_NWI";
BA_ "SysSignalName" SG_ 554 isDMSAdoWrnngDspCmd "DMSAdoWrnngDspCmd";
BA_ "ISignalName" SG_ 554 isDMSAdoWrnngDspCmd "isDMSAdoWrnngDspCmd";
BA_ "CompuMethodName" SG_ 554 isDMSAdoWrnngDspCmd "DMSAdoWrnngDspCmd";
BA_ "SysSignalName" SG_ 554 isDMSAudReq "DMSAudReq";
BA_ "ISignalName" SG_ 554 isDMSAudReq "isDMSAudReq";
BA_ "CompuMethodName" SG_ 554 isDMSAudReq "DMSAudReq";
BA_ "SysSignalName" SG_ 554 isDMSDspCmd "DMSDspCmd";
BA_ "ISignalName" SG_ 554 isDMSDspCmd "isDMSDspCmd";
BA_ "CompuMethodName" SG_ 554 isDMSDspCmd "DMSDspCmd";
BA_ "SysSignalName" SG_ 554 isDMSDstrctnAdoWrnngDspCmd "DMSDstrctnAdoWrnngDspCmd";
BA_ "ISignalName" SG_ 554 isDMSDstrctnAdoWrnngDspCmd "isDMSDstrctnAdoWrnngDspCmd";
BA_ "CompuMethodName" SG_ 554 isDMSDstrctnAdoWrnngDspCmd "DMSDstrctnAdoWrnngDspCmd";
BA_ "SysSignalName" SG_ 554 isDMSDstrctnDspCmd "DMSDstrctnDspCmd";
BA_ "ISignalName" SG_ 554 isDMSDstrctnDspCmd "isDMSDstrctnDspCmd";
BA_ "CompuMethodName" SG_ 554 isDMSDstrctnDspCmd "DMSDstrctnDspCmd";
BA_ "SysSignalName" SG_ 554 isDMSSts "DMSSts";
BA_ "ISignalName" SG_ 554 isDMSSts "isDMSSts";
BA_ "CompuMethodName" SG_ 554 isDMSSts "DMSSts";
BA_ "SysSignalName" SG_ 554 isDMSWrnngReq "DMSWrnngReq";
BA_ "ISignalName" SG_ 554 isDMSWrnngReq "isDMSWrnngReq";
BA_ "CompuMethodName" SG_ 554 isDMSWrnngReq "DMSWrnngReq";
BA_ "SysSignalName" SG_ 554 isDrvrAbnormBehvor "DrvrAbnormBehvor";
BA_ "ISignalName" SG_ 554 isDrvrAbnormBehvor "isDrvrAbnormBehvor";
BA_ "CompuMethodName" SG_ 554 isDrvrAbnormBehvor "DrvrAbnormBehvor";
BA_ "SysSignalName" SG_ 554 isDrvrDstcnSts "DrvrDstcnSts";
BA_ "ISignalName" SG_ 554 isDrvrDstcnSts "isDrvrDstcnSts";
BA_ "CompuMethodName" SG_ 554 isDrvrDstcnSts "DrvrDstcnSts";
BA_ "SysSignalName" SG_ 554 isDrvrFtgLvl "DrvrFtgLvl";
BA_ "ISignalName" SG_ 554 isDrvrFtgLvl "isDrvrFtgLvl";
BA_ "CompuMethodName" SG_ 554 isDrvrFtgLvl "DrvrFtgLvl";
BA_ "SysSignalName" SG_ 554 isDrvrGazeRgn "DrvrGazeRgn";
BA_ "ISignalName" SG_ 554 isDrvrGazeRgn "isDrvrGazeRgn";
BA_ "CompuMethodName" SG_ 554 isDrvrGazeRgn "DrvrGazeRgn";
BA_ "SysSignalName" SG_ 554 isDrvrPrst "DrvrPrst";
BA_ "ISignalName" SG_ 554 isDrvrPrst "isDrvrPrst";
BA_ "CompuMethodName" SG_ 554 isDrvrPrst "DrvrPrst";
BA_ "SysSignalName" SG_ 554 isEyeOnRoad "EyeOnRoad";
BA_ "ISignalName" SG_ 554 isEyeOnRoad "isEyeOnRoad";
BA_ "CompuMethodName" SG_ 554 isEyeOnRoad "EyeOnRoad";
BA_ "SysSignalName" SG_ 554 isSpfngDet "SpfngDet";
BA_ "ISignalName" SG_ 554 isSpfngDet "isSpfngDet";
BA_ "CompuMethodName" SG_ 554 isSpfngDet "SpfngDet";
BA_ "SysSignalName" SG_ 554 isDMSDstrctnHptWrnngDspCmd "DMSDstrctnHptWrnngDspCmd";
BA_ "ISignalName" SG_ 554 isDMSDstrctnHptWrnngDspCmd "isDMSDstrctnHptWrnngDspCmd";
BA_ "CompuMethodName" SG_ 554 isDMSDstrctnHptWrnngDspCmd "DMSDstrctnHptWrnngDspCmd";
BA_ "SysSignalName" SG_ 554 isDMSHapticWrnngDspCmd "DMSHapticWrnngDspCmd";
BA_ "ISignalName" SG_ 554 isDMSHapticWrnngDspCmd "isDMSHapticWrnngDspCmd";
BA_ "CompuMethodName" SG_ 554 isDMSHapticWrnngDspCmd "DMSHapticWrnngDspCmd";
BA_ "SysSignalName" SG_ 171 isStrgWhlAngSnsrFlt "StrgWhlAngSnsrFlt";
BA_ "ISignalName" SG_ 171 isStrgWhlAngSnsrFlt "isStrgWhlAngSnsrFlt";
BA_ "CompuMethodName" SG_ 171 isStrgWhlAngSnsrFlt "StrgWhlAngSnsrFlt";
BA_ "SysSignalName" SG_ 171 isStrgWhlAngV "StrgWhlAngV";
BA_ "ISignalName" SG_ 171 isStrgWhlAngV "isStrgWhlAngV";
BA_ "CompuMethodName" SG_ 171 isStrgWhlAngV "StrgWhlAngV";
BA_ "SysSignalName" SG_ 171 isStrgWhlAngSnsrMultCapb "StrgWhlAngSnsrMultCapb";
BA_ "ISignalName" SG_ 171 isStrgWhlAngSnsrMultCapb "isStrgWhlAngSnsrMultCapb";
BA_ "CompuMethodName" SG_ 171 isStrgWhlAngSnsrMultCapb "StrgWhlAngSnsrMultCapb";
BA_ "SysSignalName" SG_ 171 isStrgWhlAngSnsrCalSts "StrgWhlAngSnsrCalSts";
BA_ "ISignalName" SG_ 171 isStrgWhlAngSnsrCalSts "isStrgWhlAngSnsrCalSts";
BA_ "CompuMethodName" SG_ 171 isStrgWhlAngSnsrCalSts "StrgWhlAngSnsrCalSts";
BA_ "SysSignalName" SG_ 171 isStrgWhlAng "StrgWhlAng";
BA_ "ISignalName" SG_ 171 isStrgWhlAng "isStrgWhlAng";
BA_ "CompuMethodName" SG_ 171 isStrgWhlAng "StrgWhlAng";
BA_ "SysSignalName" SG_ 171 isStrgWhlAngGrd "StrgWhlAngGrd";
BA_ "ISignalName" SG_ 171 isStrgWhlAngGrd "isStrgWhlAngGrd";
BA_ "CompuMethodName" SG_ 171 isStrgWhlAngGrd "StrgWhlAngGrd";
BA_ "SysSignalName" SG_ 171 isStrgWhlAngSnsrInid "StrgWhlAngSnsrInid";
BA_ "ISignalName" SG_ 171 isStrgWhlAngSnsrInid "isStrgWhlAngSnsrInid";
BA_ "CompuMethodName" SG_ 171 isStrgWhlAngSnsrInid "StrgWhlAngSnsrInid";
BA_ "SysSignalName" SG_ 555 isSysBPM "SysBPM";
BA_ "ISignalName" SG_ 555 isSysBPM "isSysBPM";
BA_ "CompuMethodName" SG_ 555 isSysBPM "SysBPM";
BA_ "SysSignalName" SG_ 555 isSysBPMEnbd "SysBPMEnbd";
BA_ "ISignalName" SG_ 555 isSysBPMEnbd "isSysBPMEnbd";
BA_ "CompuMethodName" SG_ 555 isSysBPMEnbd "SysBPMEnbd";
BA_ "SysSignalName" SG_ 474 isLDWLKALVsulznReq "LDWLKALVsulznReq";
BA_ "ISignalName" SG_ 474 isLDWLKALVsulznReq "isLDWLKALVsulznReq";
BA_ "CompuMethodName" SG_ 474 isLDWLKALVsulznReq "LDWLKALVsulznReq";
BA_ "SysSignalName" SG_ 474 isLDWLKARVsulznReq "LDWLKARVsulznReq";
BA_ "ISignalName" SG_ 474 isLDWLKARVsulznReq "isLDWLKARVsulznReq";
BA_ "CompuMethodName" SG_ 474 isLDWLKARVsulznReq "LDWLKARVsulznReq";
BA_ "SysSignalName" SG_ 474 isLKASysSts "LKASysSts";
BA_ "ISignalName" SG_ 474 isLKASysSts "isLKASysSts";
BA_ "CompuMethodName" SG_ 474 isLKASysSts "LKASysSts";
BA_ "SysSignalName" SG_ 366 isACCSysSts "ACCSysSts";
BA_ "ISignalName" SG_ 366 isACCSysSts "isACCSysSts";
BA_ "CompuMethodName" SG_ 366 isACCSysSts "ACCSysSts";
BA_ "SysSignalName" SG_ 343 isAEBSysSts "AEBSysSts";
BA_ "ISignalName" SG_ 343 isAEBSysSts "isAEBSysSts";
BA_ "CompuMethodName" SG_ 343 isAEBSysSts "AEBSysSts";
BA_ "SysSignalName" SG_ 497 isSysOpnlMd "SysOpnlMd";
BA_ "ISignalName" SG_ 497 isSysOpnlMd "isSysOpnlMd";
BA_ "CompuMethodName" SG_ 497 isSysOpnlMd "SysOpnlMd";
BA_ "SysSignalName" SG_ 497 isSysPwrMd "SysPwrMd";
BA_ "ISignalName" SG_ 497 isSysPwrMd "isSysPwrMd";
BA_ "CompuMethodName" SG_ 497 isSysPwrMd "SysPwrMd";
BA_ "SysSignalName" SG_ 497 isSysPwrMdV "SysPwrMdV";
BA_ "ISignalName" SG_ 497 isSysPwrMdV "isSysPwrMdV";
BA_ "CompuMethodName" SG_ 497 isSysPwrMdV "SysPwrMdV";
BA_ "SysSignalName" SG_ 497 isSysVol "SysVol";
BA_ "ISignalName" SG_ 497 isSysVol "isSysVol";
BA_ "CompuMethodName" SG_ 497 isSysVol "SysVol";
BA_ "SysSignalName" SG_ 497 isSysVolMd "SysVolMd";
BA_ "ISignalName" SG_ 497 isSysVolMd "isSysVolMd";
BA_ "CompuMethodName" SG_ 497 isSysVolMd "SysVolMd";
BA_ "SysSignalName" SG_ 497 isSysVolMdV "SysVolMdV";
BA_ "ISignalName" SG_ 497 isSysVolMdV "isSysVolMdV";
BA_ "CompuMethodName" SG_ 497 isSysVolMdV "SysVolMdV";
BA_ "SysSignalName" SG_ 497 isSysVolV "SysVolV";
BA_ "ISignalName" SG_ 497 isSysVolV "isSysVolV";
BA_ "CompuMethodName" SG_ 497 isSysVolV "SysVolV";
BA_ "SysSignalName" SG_ 497 isBrkPdlDrvrAppdPrs "BrkPdlDrvrAppdPrs";
BA_ "ISignalName" SG_ 497 isBrkPdlDrvrAppdPrs "isBrkPdlDrvrAppdPrs";
BA_ "CompuMethodName" SG_ 497 isBrkPdlDrvrAppdPrs "BrkPdlDrvrAppdPrs";
BA_ "SysSignalName" SG_ 497 isBrkPdlDrvrAppdPrsV "BrkPdlDrvrAppdPrsV";
BA_ "ISignalName" SG_ 497 isBrkPdlDrvrAppdPrsV "isBrkPdlDrvrAppdPrsV";
BA_ "CompuMethodName" SG_ 497 isBrkPdlDrvrAppdPrsV "BrkPdlDrvrAppdPrsV";
BA_ "SysSignalName" SG_ 497 isBMSAvlbly "BMSAvlbly";
BA_ "ISignalName" SG_ 497 isBMSAvlbly "isBMSAvlbly";
BA_ "CompuMethodName" SG_ 497 isBMSAvlbly "BMSAvlbly";
BA_ "SysSignalName" SG_ 497 isSCSAvlbly "SCSAvlbly";
BA_ "ISignalName" SG_ 497 isSCSAvlbly "isSCSAvlbly";
BA_ "CompuMethodName" SG_ 497 isSCSAvlbly "SCSAvlbly";
BA_ "SysSignalName" SG_ 497 isVCUAvlbly "VCUAvlbly";
BA_ "ISignalName" SG_ 497 isVCUAvlbly "isVCUAvlbly";
BA_ "CompuMethodName" SG_ 497 isVCUAvlbly "VCUAvlbly";
BA_ "SysSignalName" SG_ 497 isIPKAvlbly "IPKAvlbly";
BA_ "ISignalName" SG_ 497 isIPKAvlbly "isIPKAvlbly";
BA_ "CompuMethodName" SG_ 497 isIPKAvlbly "IPKAvlbly";
BA_ "SysSignalName" SG_ 497 isFICMAvlbly "FICMAvlbly";
BA_ "ISignalName" SG_ 497 isFICMAvlbly "isFICMAvlbly";
BA_ "CompuMethodName" SG_ 497 isFICMAvlbly "FICMAvlbly";
BA_ "SysSignalName" SG_ 497 isBCMAvlbly "BCMAvlbly";
BA_ "ISignalName" SG_ 497 isBCMAvlbly "isBCMAvlbly";
BA_ "CompuMethodName" SG_ 497 isBCMAvlbly "BCMAvlbly";
BA_ "SysSignalName" SG_ 497 isSDMAvlbly "SDMAvlbly";
BA_ "ISignalName" SG_ 497 isSDMAvlbly "isSDMAvlbly";
BA_ "CompuMethodName" SG_ 497 isSDMAvlbly "SDMAvlbly";
BA_ "SysSignalName" SG_ 497 isADASAvlbly "ADASAvlbly";
BA_ "ISignalName" SG_ 497 isADASAvlbly "isADASAvlbly";
BA_ "CompuMethodName" SG_ 497 isADASAvlbly "ADASAvlbly";
BA_ "SysSignalName" SG_ 497 isEPSAvlbly "EPSAvlbly";
BA_ "ISignalName" SG_ 497 isEPSAvlbly "isEPSAvlbly";
BA_ "CompuMethodName" SG_ 497 isEPSAvlbly "EPSAvlbly";
BA_ "SysSignalName" SG_ 497 isTCAvlbly "TCAvlbly";
BA_ "ISignalName" SG_ 497 isTCAvlbly "isTCAvlbly";
BA_ "CompuMethodName" SG_ 497 isTCAvlbly "TCAvlbly";
BA_ "SysSignalName" SG_ 497 isSASAvlbly "SASAvlbly";
BA_ "ISignalName" SG_ 497 isSASAvlbly "isSASAvlbly";
BA_ "CompuMethodName" SG_ 497 isSASAvlbly "SASAvlbly";
BA_ "SysSignalName" SG_ 497 isTBOXAvlbly "TBOXAvlbly";
BA_ "ISignalName" SG_ 497 isTBOXAvlbly "isTBOXAvlbly";
BA_ "CompuMethodName" SG_ 497 isTBOXAvlbly "TBOXAvlbly";
BA_ "SysSignalName" SG_ 497 isACAvlbly "ACAvlbly";
BA_ "ISignalName" SG_ 497 isACAvlbly "isACAvlbly";
BA_ "CompuMethodName" SG_ 497 isACAvlbly "ACAvlbly";
BA_ "SysSignalName" SG_ 497 isEPBAvlbly "EPBAvlbly";
BA_ "ISignalName" SG_ 497 isEPBAvlbly "isEPBAvlbly";
BA_ "CompuMethodName" SG_ 497 isEPBAvlbly "EPBAvlbly";
BA_ "SysSignalName" SG_ 497 isSCUAvlbly "SCUAvlbly";
BA_ "ISignalName" SG_ 497 isSCUAvlbly "isSCUAvlbly";
BA_ "CompuMethodName" SG_ 497 isSCUAvlbly "SCUAvlbly";
BA_ "SysSignalName" SG_ 497 isTPMSAvlbly "TPMSAvlbly";
BA_ "ISignalName" SG_ 497 isTPMSAvlbly "isTPMSAvlbly";
BA_ "CompuMethodName" SG_ 497 isTPMSAvlbly "TPMSAvlbly";
BA_ "SysSignalName" SG_ 497 isDMSAvlbly "DMSAvlbly";
BA_ "ISignalName" SG_ 497 isDMSAvlbly "isDMSAvlbly";
BA_ "CompuMethodName" SG_ 497 isDMSAvlbly "DMSAvlbly";
BA_ "SysSignalName" SG_ 497 isCCUAvlbly "CCUAvlbly";
BA_ "ISignalName" SG_ 497 isCCUAvlbly "isCCUAvlbly";
BA_ "CompuMethodName" SG_ 497 isCCUAvlbly "CCUAvlbly";
BA_ "SysSignalName" SG_ 497 isESCLAvlbly "ESCLAvlbly";
BA_ "ISignalName" SG_ 497 isESCLAvlbly "isESCLAvlbly";
BA_ "CompuMethodName" SG_ 497 isESCLAvlbly "ESCLAvlbly";
BA_ "SysSignalName" SG_ 497 isRDAAvlbly "RDAAvlbly";
BA_ "ISignalName" SG_ 497 isRDAAvlbly "isRDAAvlbly";
BA_ "CompuMethodName" SG_ 497 isRDAAvlbly "RDAAvlbly";
BA_ "SysSignalName" SG_ 497 isPLCMAvlbly "PLCMAvlbly";
BA_ "ISignalName" SG_ 497 isPLCMAvlbly "isPLCMAvlbly";
BA_ "CompuMethodName" SG_ 497 isPLCMAvlbly "PLCMAvlbly";
BA_ "SysSignalName" SG_ 497 isTDMAvlbly "TDMAvlbly";
BA_ "ISignalName" SG_ 497 isTDMAvlbly "isTDMAvlbly";
BA_ "CompuMethodName" SG_ 497 isTDMAvlbly "TDMAvlbly";
BA_ "SysSignalName" SG_ 497 isRCPDAvlbly "RCPDAvlbly";
BA_ "ISignalName" SG_ 497 isRCPDAvlbly "isRCPDAvlbly";
BA_ "CompuMethodName" SG_ 497 isRCPDAvlbly "RCPDAvlbly";
BA_ "SysSignalName" SG_ 1142 isCalendarDay "CalendarDay";
BA_ "ISignalName" SG_ 1142 isCalendarDay "isCalendarDay";
BA_ "CompuMethodName" SG_ 1142 isCalendarDay "CalendarDay";
BA_ "SysSignalName" SG_ 1142 isCalendarMonth "CalendarMonth";
BA_ "ISignalName" SG_ 1142 isCalendarMonth "isCalendarMonth";
BA_ "CompuMethodName" SG_ 1142 isCalendarMonth "CalendarMonth";
BA_ "SysSignalName" SG_ 1142 isCalendarYear "CalendarYear";
BA_ "ISignalName" SG_ 1142 isCalendarYear "isCalendarYear";
BA_ "CompuMethodName" SG_ 1142 isCalendarYear "CalendarYear";
BA_ "SysSignalName" SG_ 1142 isHourOfDay "HourOfDay";
BA_ "ISignalName" SG_ 1142 isHourOfDay "isHourOfDay";
BA_ "CompuMethodName" SG_ 1142 isHourOfDay "HourOfDay";
BA_ "SysSignalName" SG_ 1142 isMinuteOfHour "MinuteOfHour";
BA_ "ISignalName" SG_ 1142 isMinuteOfHour "isMinuteOfHour";
BA_ "CompuMethodName" SG_ 1142 isMinuteOfHour "MinuteOfHour";
BA_ "SysSignalName" SG_ 1142 isSecsOfMinute "SecsOfMinute";
BA_ "ISignalName" SG_ 1142 isSecsOfMinute "isSecsOfMinute";
BA_ "CompuMethodName" SG_ 1142 isSecsOfMinute "SecsOfMinute";
BA_ "SysSignalName" SG_ 1142 isTimeDspFmt "TimeDspFmt";
BA_ "ISignalName" SG_ 1142 isTimeDspFmt "isTimeDspFmt";
BA_ "CompuMethodName" SG_ 1142 isTimeDspFmt "TimeDspFmt";
BA_ "SysSignalName" SG_ 451 isClstrDspdVehSpd "ClstrDspdVehSpd";
BA_ "ISignalName" SG_ 451 isClstrDspdVehSpd "isClstrDspdVehSpd";
BA_ "CompuMethodName" SG_ 451 isClstrDspdVehSpd "ClstrDspdVehSpd";
BA_ "SysSignalName" SG_ 451 isDspMeasSys "DspMeasSys";
BA_ "ISignalName" SG_ 451 isDspMeasSys "isDspMeasSys";
BA_ "CompuMethodName" SG_ 451 isDspMeasSys "DspMeasSys";
BA_ "SysSignalName" SG_ 814 isVehPwrCsumpMd "VehPwrCsumpMd";
BA_ "ISignalName" SG_ 814 isVehPwrCsumpMd "isVehPwrCsumpMd";
BA_ "CompuMethodName" SG_ 814 isVehPwrCsumpMd "VehPwrCsumpMd";
BA_ "SysSignalName" SG_ 814 isDMSAdoWrnngReq "DMSAdoWrnngReq";
BA_ "ISignalName" SG_ 814 isDMSAdoWrnngReq "isDMSAdoWrnngReq";
BA_ "CompuMethodName" SG_ 814 isDMSAdoWrnngReq "DMSAdoWrnngReq";
BA_ "SysSignalName" SG_ 814 isDMSHapticWrnngReq "DMSHapticWrnngReq";
BA_ "ISignalName" SG_ 814 isDMSHapticWrnngReq "isDMSHapticWrnngReq";
BA_ "CompuMethodName" SG_ 814 isDMSHapticWrnngReq "DMSHapticWrnngReq";
BA_ "SysSignalName" SG_ 814 isDMSSwReq "DMSSwReq";
BA_ "ISignalName" SG_ 814 isDMSSwReq "isDMSSwReq";
BA_ "CompuMethodName" SG_ 814 isDMSSwReq "DMSSwReq";
BA_ "SysSignalName" SG_ 814 isFOTASts "FOTASts";
BA_ "ISignalName" SG_ 814 isFOTASts "isFOTASts";
BA_ "CompuMethodName" SG_ 814 isFOTASts "FOTASts";
BA_ "SysSignalName" SG_ 814 isFOTAStsV "FOTAStsV";
BA_ "ISignalName" SG_ 814 isFOTAStsV "isFOTAStsV";
BA_ "CompuMethodName" SG_ 814 isFOTAStsV "FOTAStsV";
BA_ "SysSignalName" SG_ 814 isLDircnIndLghtF "LDircnIndLghtF";
BA_ "ISignalName" SG_ 814 isLDircnIndLghtF "isLDircnIndLghtF";
BA_ "CompuMethodName" SG_ 814 isLDircnIndLghtF "LDircnIndLghtF";
BA_ "SysSignalName" SG_ 814 isRDircnIndLghtF "RDircnIndLghtF";
BA_ "ISignalName" SG_ 814 isRDircnIndLghtF "isRDircnIndLghtF";
BA_ "CompuMethodName" SG_ 814 isRDircnIndLghtF "RDircnIndLghtF";
BA_ "SysSignalName" SG_ 814 isDircnIndLampSwSts "DircnIndLampSwSts";
BA_ "ISignalName" SG_ 814 isDircnIndLampSwSts "isDircnIndLampSwSts";
BA_ "CompuMethodName" SG_ 814 isDircnIndLampSwSts "DircnIndLampSwSts";
BA_ "SysSignalName" SG_ 814 isRstrFctryDeftsReq "RstrFctryDeftsReq";
BA_ "ISignalName" SG_ 814 isRstrFctryDeftsReq "isRstrFctryDeftsReq";
BA_ "CompuMethodName" SG_ 814 isRstrFctryDeftsReq "RstrFctryDeftsReq";
BA_ "SysSignalName" SG_ 812 isDrvrDoorOpenSts "DrvrDoorOpenSts";
BA_ "ISignalName" SG_ 812 isDrvrDoorOpenSts "isDrvrDoorOpenSts";
BA_ "CompuMethodName" SG_ 812 isDrvrDoorOpenSts "DrvrDoorOpenSts";
BA_ "SysSignalName" SG_ 165 isBrkPdlAppd "BrkPdlAppd";
BA_ "ISignalName" SG_ 165 isBrkPdlAppd "isBrkPdlAppd";
BA_ "CompuMethodName" SG_ 165 isBrkPdlAppd "BrkPdlAppd";
BA_ "SysSignalName" SG_ 165 isBrkPdlAppdV "BrkPdlAppdV";
BA_ "ISignalName" SG_ 165 isBrkPdlAppdV "isBrkPdlAppdV";
BA_ "CompuMethodName" SG_ 165 isBrkPdlAppdV "BrkPdlAppdV";
BA_ "SysSignalName" SG_ 165 isDrvrReqOtptRodTrvl "DrvrReqOtptRodTrvl";
BA_ "ISignalName" SG_ 165 isDrvrReqOtptRodTrvl "isDrvrReqOtptRodTrvl";
BA_ "CompuMethodName" SG_ 165 isDrvrReqOtptRodTrvl "DrvrReqOtptRodTrvl";
BA_ "SysSignalName" SG_ 165 isDrvrReqOtptRodTrvlSts "DrvrReqOtptRodTrvlSts";
BA_ "ISignalName" SG_ 165 isDrvrReqOtptRodTrvlSts "isDrvrReqOtptRodTrvlSts";
BA_ "CompuMethodName" SG_ 165 isDrvrReqOtptRodTrvlSts "DrvrReqOtptRodTrvlSts";
BA_ "SysSignalName" SG_ 318 isVehSpdAvg "VehSpdAvg";
BA_ "ISignalName" SG_ 318 isVehSpdAvg "isVehSpdAvg";
BA_ "CompuMethodName" SG_ 318 isVehSpdAvg "VehSpdAvg";
BA_ "SysSignalName" SG_ 318 isVehSpdAvgDrvn "VehSpdAvgDrvn";
BA_ "ISignalName" SG_ 318 isVehSpdAvgDrvn "isVehSpdAvgDrvn";
BA_ "CompuMethodName" SG_ 318 isVehSpdAvgDrvn "VehSpdAvgDrvn";
BA_ "SysSignalName" SG_ 318 isVehSpdAvgDrvnV "VehSpdAvgDrvnV";
BA_ "ISignalName" SG_ 318 isVehSpdAvgDrvnV "isVehSpdAvgDrvnV";
BA_ "CompuMethodName" SG_ 318 isVehSpdAvgDrvnV "VehSpdAvgDrvnV";
BA_ "SysSignalName" SG_ 318 isVehSpdAvgNonDrvn "VehSpdAvgNonDrvn";
BA_ "ISignalName" SG_ 318 isVehSpdAvgNonDrvn "isVehSpdAvgNonDrvn";
BA_ "CompuMethodName" SG_ 318 isVehSpdAvgNonDrvn "VehSpdAvgNonDrvn";
BA_ "SysSignalName" SG_ 318 isVehSpdAvgNonDrvnV "VehSpdAvgNonDrvnV";
BA_ "ISignalName" SG_ 318 isVehSpdAvgNonDrvnV "isVehSpdAvgNonDrvnV";
BA_ "CompuMethodName" SG_ 318 isVehSpdAvgNonDrvnV "VehSpdAvgNonDrvnV";
BA_ "SysSignalName" SG_ 318 isVehSpdAvgV "VehSpdAvgV";
BA_ "ISignalName" SG_ 318 isVehSpdAvgV "isVehSpdAvgV";
BA_ "CompuMethodName" SG_ 318 isVehSpdAvgV "VehSpdAvgV";
BA_ "SysSignalName" SG_ 318 isDrvrSbltAtc "DrvrSbltAtc";
BA_ "ISignalName" SG_ 318 isDrvrSbltAtc "isDrvrSbltAtc";
BA_ "CompuMethodName" SG_ 318 isDrvrSbltAtc "DrvrSbltAtc";
BA_ "SysSignalName" SG_ 318 isDrvrSbltAtcV "DrvrSbltAtcV";
BA_ "ISignalName" SG_ 318 isDrvrSbltAtcV "isDrvrSbltAtcV";
BA_ "CompuMethodName" SG_ 318 isDrvrSbltAtcV "DrvrSbltAtcV";
BA_ "SysSignalName" SG_ 70 isEPTAccelActuPos "EPTAccelActuPos";
BA_ "ISignalName" SG_ 70 isEPTAccelActuPos "isEPTAccelActuPos";
BA_ "CompuMethodName" SG_ 70 isEPTAccelActuPos "EPTAccelActuPos";
BA_ "SysSignalName" SG_ 70 isEPTAccelActuPosV "EPTAccelActuPosV";
BA_ "ISignalName" SG_ 70 isEPTAccelActuPosV "isEPTAccelActuPosV";
BA_ "CompuMethodName" SG_ 70 isEPTAccelActuPosV "EPTAccelActuPosV";
BA_ "SysSignalName" SG_ 70 isEPTBrkPdlDscrtInptStsV "EPTBrkPdlDscrtInptStsV";
BA_ "ISignalName" SG_ 70 isEPTBrkPdlDscrtInptStsV "isEPTBrkPdlDscrtInptStsV";
BA_ "CompuMethodName" SG_ 70 isEPTBrkPdlDscrtInptStsV "EPTBrkPdlDscrtInptStsV";
BA_ "SysSignalName" SG_ 70 isEPTBrkPdlDscrtInptSts "EPTBrkPdlDscrtInptSts";
BA_ "ISignalName" SG_ 70 isEPTBrkPdlDscrtInptSts "isEPTBrkPdlDscrtInptSts";
BA_ "CompuMethodName" SG_ 70 isEPTBrkPdlDscrtInptSts "EPTBrkPdlDscrtInptSts";
BA_ "SysSignalName" SG_ 70 isEPTRdy "EPTRdy";
BA_ "ISignalName" SG_ 70 isEPTRdy "isEPTRdy";
BA_ "CompuMethodName" SG_ 70 isEPTRdy "EPTRdy";
BA_ "SysSignalName" SG_ 70 isEPTStCmdOn "EPTStCmdOn";
BA_ "ISignalName" SG_ 70 isEPTStCmdOn "isEPTStCmdOn";
BA_ "CompuMethodName" SG_ 70 isEPTStCmdOn "EPTStCmdOn";
BA_ "SysSignalName" SG_ 404 isTrShftLvrPosV "TrShftLvrPosV";
BA_ "ISignalName" SG_ 404 isTrShftLvrPosV "isTrShftLvrPosV";
BA_ "CompuMethodName" SG_ 404 isTrShftLvrPosV "TrShftLvrPosV";
BA_ "SysSignalName" SG_ 404 isTrShftLvrPos "TrShftLvrPos";
BA_ "ISignalName" SG_ 404 isTrShftLvrPos "isTrShftLvrPos";
BA_ "CompuMethodName" SG_ 404 isTrShftLvrPos "TrShftLvrPos";
BA_ "SysSignalName" SG_ 319 isVehDynYawRateV "VehDynYawRateV";
BA_ "ISignalName" SG_ 319 isVehDynYawRateV "isVehDynYawRateV";
BA_ "CompuMethodName" SG_ 319 isVehDynYawRateV "VehDynYawRateV";
BA_ "SysSignalName" SG_ 319 isVehDynYawRate "VehDynYawRate";
BA_ "ISignalName" SG_ 319 isVehDynYawRate "isVehDynYawRate";
BA_ "CompuMethodName" SG_ 319 isVehDynYawRate "VehDynYawRate";
BA_ "SysSignalName" SG_ 319 isVSELatAcc "VSELatAcc";
BA_ "ISignalName" SG_ 319 isVSELatAcc "isVSELatAcc";
BA_ "CompuMethodName" SG_ 319 isVSELatAcc "VSELatAcc";
BA_ "SysSignalName" SG_ 319 isVSELatAccV "VSELatAccV";
BA_ "ISignalName" SG_ 319 isVSELatAccV "isVSELatAccV";
BA_ "CompuMethodName" SG_ 319 isVSELatAccV "VSELatAccV";
BA_ "SysSignalName" SG_ 319 isVSELongtAcc "VSELongtAcc";
BA_ "ISignalName" SG_ 319 isVSELongtAcc "isVSELongtAcc";
BA_ "CompuMethodName" SG_ 319 isVSELongtAcc "VSELongtAcc";
BA_ "SysSignalName" SG_ 319 isVSELongtAccV "VSELongtAccV";
BA_ "ISignalName" SG_ 319 isVSELongtAccV "isVSELongtAccV";
BA_ "CompuMethodName" SG_ 319 isVSELongtAccV "VSELongtAccV";
BA_ "SysSignalName" SG_ 1352 isVehOdo "VehOdo";
BA_ "ISignalName" SG_ 1352 isVehOdo "isVehOdo";
BA_ "CompuMethodName" SG_ 1352 isVehOdo "VehOdo";
BA_ "SysSignalName" SG_ 1352 isVehOdoV "VehOdoV";
BA_ "ISignalName" SG_ 1352 isVehOdoV "isVehOdoV";
BA_ "CompuMethodName" SG_ 1352 isVehOdoV "VehOdoV";
BA_ "SysSignalName" SG_ 924 isDMSDstrctnAdoWrnngReq "DMSDstrctnAdoWrnngReq";
BA_ "ISignalName" SG_ 924 isDMSDstrctnAdoWrnngReq "isDMSDstrctnAdoWrnngReq";
BA_ "CompuMethodName" SG_ 924 isDMSDstrctnAdoWrnngReq "DMSDstrctnAdoWrnngReq";
BA_ "SysSignalName" SG_ 924 isDMSDstrctnHptWrnngReq "DMSDstrctnHptWrnngReq";
BA_ "ISignalName" SG_ 924 isDMSDstrctnHptWrnngReq "isDMSDstrctnHptWrnngReq";
BA_ "CompuMethodName" SG_ 924 isDMSDstrctnHptWrnngReq "DMSDstrctnHptWrnngReq";
BA_ "SysSignalName" SG_ 924 isDMSDstrctnSwReq "DMSDstrctnSwReq";
BA_ "ISignalName" SG_ 924 isDMSDstrctnSwReq "isDMSDstrctnSwReq";
BA_ "CompuMethodName" SG_ 924 isDMSDstrctnSwReq "DMSDstrctnSwReq";
BA_ "SysSignalName" SG_ 192 isDrvrStrgDlvrdToq "DrvrStrgDlvrdToq";
BA_ "ISignalName" SG_ 192 isDrvrStrgDlvrdToq "isDrvrStrgDlvrdToq";
BA_ "CompuMethodName" SG_ 192 isDrvrStrgDlvrdToq "DrvrStrgDlvrdToq";
BA_ "SysSignalName" SG_ 192 isDrvrStrgDlvrdToqV "DrvrStrgDlvrdToqV";
BA_ "ISignalName" SG_ 192 isDrvrStrgDlvrdToqV "isDrvrStrgDlvrdToqV";
BA_ "CompuMethodName" SG_ 192 isDrvrStrgDlvrdToqV "DrvrStrgDlvrdToqV";
BA_ "SysSignalName" SG_ 192 isLDircnIO "LDircnIO";
BA_ "ISignalName" SG_ 192 isLDircnIO "isLDircnIO";
BA_ "CompuMethodName" SG_ 192 isLDircnIO "LDircnIO";
BA_ "SysSignalName" SG_ 192 isRDircnIO "RDircnIO";
BA_ "ISignalName" SG_ 192 isRDircnIO "isRDircnIO";
BA_ "CompuMethodName" SG_ 192 isRDircnIO "RDircnIO";
BA_ "SysSignalName" SG_ 302 isVSELatAccV_SDM "VSELatAccV_SDM";
BA_ "ISignalName" SG_ 302 isVSELatAccV_SDM "isVSELatAccV_SDM";
BA_ "CompuMethodName" SG_ 302 isVSELatAccV_SDM "VSELatAccV_SDM";
BA_ "SysSignalName" SG_ 302 isVehDynYawRate_SDM "VehDynYawRate_SDM";
BA_ "ISignalName" SG_ 302 isVehDynYawRate_SDM "isVehDynYawRate_SDM";
BA_ "CompuMethodName" SG_ 302 isVehDynYawRate_SDM "VehDynYawRate_SDM";
BA_ "SysSignalName" SG_ 302 isVSELongtAccV_SDM "VSELongtAccV_SDM";
BA_ "ISignalName" SG_ 302 isVSELongtAccV_SDM "isVSELongtAccV_SDM";
BA_ "CompuMethodName" SG_ 302 isVSELongtAccV_SDM "VSELongtAccV_SDM";
BA_ "SysSignalName" SG_ 302 isVSELongtAcc_SDM "VSELongtAcc_SDM";
BA_ "ISignalName" SG_ 302 isVSELongtAcc_SDM "isVSELongtAcc_SDM";
BA_ "CompuMethodName" SG_ 302 isVSELongtAcc_SDM "VSELongtAcc_SDM";
BA_ "SysSignalName" SG_ 302 isVSELatAcc_SDM "VSELatAcc_SDM";
BA_ "ISignalName" SG_ 302 isVSELatAcc_SDM "isVSELatAcc_SDM";
BA_ "CompuMethodName" SG_ 302 isVSELatAcc_SDM "VSELatAcc_SDM";
BA_ "SysSignalName" SG_ 302 isVehDynYawRateV_SDM "VehDynYawRateV_SDM";
BA_ "ISignalName" SG_ 302 isVehDynYawRateV_SDM "isVehDynYawRateV_SDM";
BA_ "CompuMethodName" SG_ 302 isVehDynYawRateV_SDM "VehDynYawRateV_SDM";
VAL_ 1240 isDMS_NM_BSMtoRMS 0 "False" 1 "True" ;
VAL_ 1240 isDMS_NM_NOSSta 0 "False" 1 "True" ;
VAL_ 1240 isDMS_NM_NOStoRMS 0 "False" 1 "True" ;
VAL_ 1240 isDMS_NM_PBSMtoRMS 0 "False" 1 "True" ;
VAL_ 1240 isDMS_NM_RMSSta 0 "False" 1 "True" ;
VAL_ 1240 isDMS_NM_RMStoNOS 0 "False" 1 "True" ;
VAL_ 1240 isDMS_NM_RSStoNOS 0 "False" 1 "True" ;
VAL_ 1240 isDMS_NM_RSStoRMS 0 "False" 1 "True" ;
VAL_ 1216 isBCM_NM_BSMtoRMS_AD 0 "False" 1 "True" ;
VAL_ 1216 isBCM_NM_NOSSta_AD 0 "False" 1 "True" ;
VAL_ 1216 isBCM_NM_NOStoRMS_AD 0 "False" 1 "True" ;
VAL_ 1216 isBCM_NM_PBSMtoRMS_AD 0 "False" 1 "True" ;
VAL_ 1216 isBCM_NM_RMSSta_AD 0 "False" 1 "True" ;
VAL_ 1216 isBCM_NM_RMStoNOS_AD 0 "False" 1 "True" ;
VAL_ 1216 isBCM_NM_RSStoNOS_AD 0 "False" 1 "True" ;
VAL_ 1216 isBCM_NM_RSStoRMS_AD 0 "False" 1 "True" ;
VAL_ 1216 isBGM_NWI_AD 0 "BGM_NWI_0_NoWakeNetworkSource" 1 "BGM_NWI_1_PowerModeIsRun_crank" 2 "BGM_NWI_2_BrakePedalSwitchPressedRequest" 3 "BGM_NWI_3_OccupationSensorActive" 4 "BGM_NWI_4_HazardSwitchPressedRequest" 5 "BGM_NWI_5_MasterLockSwitchLockRequest" 6 "BGM_NWI_6_MasterLockSwitchUnlockRequest" 7 "BGM_NWI_7_BonnetContactSwitchOpenRequest" 8 "BGM_NWI_8_BonnetContactSwitchCloseRequest" 9 "BGM_NWI_9_LoadspaceReleaseSwitchPressed" 10 "BGM_NWI_10_LoadspaceOpenSwitchOpenRequest" 11 "BGM_NWI_11_KeyLockRequest" 12 "BGM_NWI_12_RKEUnlockRequest" 13 "BGM_NWI_13_KeyUnlockRequest" 14 "BGM_NWI_14_RKELockRequest" 15 "BGM_NWI_15_RKEBootUnlockRequest" 16 "BGM_NWI_16_RKEBonnetUnlockRequest" 17 "BGM_NWI_17_KickSensorRequest" 18 "BGM_NWI_18_DriverDoorAjarSwitchOpenRequest" 19 "BGM_NWI_19_DriverDoorAjarSwitchCloseRequest" 20 "BGM_NWI_20_FrontPassengerDoorAjarSwitchOpenRequest" 21 "BGM_NWI_21_FrontPassengerDoorAjarSwitchCloseRequest" 22 "BGM_NWI_22_RearLeftDoorAjarSwitchOpenRequest" 23 "BGM_NWI_23_RearLeftDoorAjarSwitchCloseRequest" 24 "BGM_NWI_24_RearRightDoorAjarSwitchOpenRequest" 25 "BGM_NWI_25_RearRightDoorAjarSwitchCloseRequest" 26 "BGM_NWI_26_LoadspaceOpenSwitchCloseRequest" 27 "BGM_NWI_27_PositionLampSwitchOnRequest" 28 "BGM_NWI_28_DriverDoorHandleSwitchRequest" 29 "BGM_NWI_29_FrontPassengerDoorHandleSwitchRequest" 30 "BGM_NWI_30_RLDoorHandleSwitchRequest" 31 "BGM_NWI_31_RRDoorHandleSwitchRequest" 32 "BGM_NWI_32_DLISACCSwitchInput" 33 "BGM_NWI_33_DISwitchInput" 34 "BGM_NWI_34_PositionLampSwitchOffRequest" 35 "BGM_NWI_35_ClutchBottomSwitchPressedRequest" 36 "BGM_NWI_36_SSBSwitchRequest" 37 "BGM_NWI_37_RKEPanicButton" 38 "BGM_NWI_38_RKERVSButton" 39 "BGM_NWI_39_RKEFrontLeftPowerDoorControlSwitchActive" 40 "BGM_NWI_40_RKEFrontRightPowerDoorControlSwitchActive" 41 "BGM_NWI_41_RKERPASwitchActive" 42 "BGM_NWI_42_LeftLowerConsolePowerDoorOpenSwitch" 43 "BGM_NWI_43_LeftLowerConsolePowerDoorCloseSwitch" 44 "BGM_NWI_44_LeftLocalPowerDoorOpenSwitch" 45 "BGM_NWI_45_LeftLocalPowerDoorCloseSwitch" 46 "BGM_NWI_46_RightLowerConsolePowerDoorOpenSwitch" 47 "BGM_NWI_47_RightLowerConsolePowerDoorCloseSwitch" 48 "BGM_NWI_48_RightLocalPowerDoorOpenSwitch" 49 "BGM_NWI_49_RightLocalPowerDoorCloseSwitch" 50 "BGM_NWI_50_IgnitionHardwireActive" 51 "BGM_NWI_51_DLISACCSwitchInput" 52 "BGM_NWI_52_DLISRUNCrankSwitchInput" 53 "BGM_NWI_53_KL30PowerUp" 54 "BGM_NWI_54_GWDiagnosticActive" 55 "BGM_NWI_55_DoIPHardwireActive" 56 "BGM_NWI_56_EBSBatterySOCLow" 57 "BGM_NWI_57_NodeNetworkWakeupRequirment" ;
VAL_ 554 isDMSAdoWrnngDspCmd 0 "DMSAdoWrnngDspCmd_0_Unavailable" 1 "DMSAdoWrnngDspCmd_1_Off" 2 "DMSAdoWrnngDspCmd_2_On" 3 "DMSAdoWrnngDspCmd_3_laststatus" ;
VAL_ 554 isDMSAudReq 0 "DMSAudReq_0_Norequest" 1 "DMSAudReq_1_Low" 2 "DMSAudReq_2_Middle" 3 "DMSAudReq_3_High" ;
VAL_ 554 isDMSDspCmd 0 "DMSDspCmd_0_Unavailable" 1 "DMSDspCmd_1_Off" 2 "DMSDspCmd_2_On" 3 "DMSDspCmd_3_reserved" ;
VAL_ 554 isDMSDstrctnAdoWrnngDspCmd 0 "DMSDstrctnAdoWrnngDspCmd_0_Unavailable" 1 "DMSDstrctnAdoWrnngDspCmd_1_Off" 2 "DMSDstrctnAdoWrnngDspCmd_2_On" 3 "DMSDstrctnAdoWrnngDspCmd_3_reserved" ;
VAL_ 554 isDMSDstrctnDspCmd 0 "DMSDstrctnDspCmd_0_Unavailable" 1 "DMSDstrctnDspCmd_1_Off" 2 "DMSDstrctnDspCmd_2_On" 3 "DMSDstrctnDspCmd_3_reserved" ;
VAL_ 554 isDMSSts 0 "DMSSts_0_Off" 1 "DMSSts_1_Standby" 2 "DMSSts_2_Active" 3 "DMSSts_3_Camera_Blocked" 4 "DMSSts_4_System_temporary_unavailable" 5 "DMSSts_5_Service_required" 6 "DMSSts_6_InitializatiOn" 7 "DMSSts_7_Performance_Degradation" ;
VAL_ 554 isDMSWrnngReq 0 "DMSWrnngReq_0_Norequest" 1 "DMSWrnngReq_1_Fatiguerequest" 2 "DMSWrnngReq_2_Distractionrequest" ;
VAL_ 554 isDrvrAbnormBehvor 0 "DrvrAbnormBehvor_0_Unknown" 1 "DrvrAbnormBehvor_1_Noabnormalbehaviour" 2 "DrvrAbnormBehvor_2_Telephonecalls" 3 "DrvrAbnormBehvor_3_Smoking" 4 "DrvrAbnormBehvor_4_Drinking" 5 "DrvrAbnormBehvor_5_Eating" ;
VAL_ 554 isDrvrDstcnSts 0 "DrvrDstcnSts_0_Unknown" 1 "DrvrDstcnSts_1_Nodistraction" 2 "DrvrDstcnSts_2_Lowleveldistraction" 3 "DrvrDstcnSts_3_Middleleveldistraction" 4 "DrvrDstcnSts_4_Highleveldistraction" ;
VAL_ 554 isDrvrFtgLvl 0 "DrvrFtgLvl_0_Unknown" 1 "DrvrFtgLvl_1_NoDrowsiness" 2 "DrvrFtgLvl_2_LowlevelDrowsiness" 3 "DrvrFtgLvl_3_MiddlelevelDrowsiness" 4 "DrvrFtgLvl_4_HighlevelDrowsiness" ;
VAL_ 554 isDrvrGazeRgn 0 "DrvrGazeRgn_0_Init_Unknown" 1 "DrvrGazeRgn_1_Driver_Side_of_Windscreen" 2 "DrvrGazeRgn_2_Copilot_Side_of_Windscreen" 3 "DrvrGazeRgn_3_Left_Rear_View_Mirror" 4 "DrvrGazeRgn_4_Right_Rear_View_Mirror" 5 "DrvrGazeRgn_5_Left_Side_Window" 6 "DrvrGazeRgn_6_Right_Side_Window" 7 "DrvrGazeRgn_7_Central_Rear_View_Mirror" 8 "DrvrGazeRgn_8_Central_driver_s_Instrument_Cluster" 9 "DrvrGazeRgn_9_Head_up_display" 10 "DrvrGazeRgn_10_Navigation_Display" 11 "DrvrGazeRgn_11_Middle_Instrument_Cluster" 12 "DrvrGazeRgn_12_Steering_Wheel" 13 "DrvrGazeRgn_13_Left_Seat_Foot_Area" 14 "DrvrGazeRgn_14_Right_Seat_Foot_Area_Workbench" 15 "DrvrGazeRgn_15_Left_Side_door_area" 16 "DrvrGazeRgn_16_Right_Side_door_area" 17 "DrvrGazeRgn_17_reserved" 18 "DrvrGazeRgn_18_reserved" 19 "DrvrGazeRgn_19_reserved" 20 "DrvrGazeRgn_20_reserved" 21 "DrvrGazeRgn_21_reserved" ;
VAL_ 554 isDrvrPrst 0 "DrvrPrst_0_Unknown" 1 "DrvrPrst_1_DriverNotPresence" 2 "DrvrPrst_2_DriverPresence" ;
VAL_ 554 isEyeOnRoad 0 "EyeOnRoad_0_Unavailable" 1 "EyeOnRoad_1_EyesOnRoad" 2 "EyeOnRoad_2_EyesOffRoad_drivingtaskrelatedregion" 3 "EyeOnRoad_3_EyesOffRoad_non_drivingtaskrelatedregion" ;
VAL_ 554 isSpfngDet 0 "SpfngDet_0_Unknown" 1 "SpfngDet_1_NotDetected" 2 "SpfngDet_2_Detected" 3 "SpfngDet_3_Reserve" ;
VAL_ 554 isDMSDstrctnHptWrnngDspCmd 0 "DMSDstrctnHptWrnngDspCmd_0_Unavailable" 1 "DMSDstrctnHptWrnngDspCmd_1_Off" 2 "DMSDstrctnHptWrnngDspCmd_2_On" 3 "DMSDstrctnHptWrnngDspCmd_3_reserved" ;
VAL_ 554 isDMSHapticWrnngDspCmd 0 "DMSHapticWrnngDspCmd_0_Unavailable" 1 "DMSHapticWrnngDspCmd_1_Off" 2 "DMSHapticWrnngDspCmd_2_On" 3 "DMSHapticWrnngDspCmd_3_laststatus" ;
VAL_ 171 isStrgWhlAngSnsrFlt 0 "StrgWhlAngSnsrFlt_0_False" 1 "StrgWhlAngSnsrFlt_1_True" ;
VAL_ 171 isStrgWhlAngV 0 "StrgWhlAngV_0_Valid" 1 "StrgWhlAngV_1_Invalid" ;
VAL_ 171 isStrgWhlAngSnsrMultCapb 0 "StrgWhlAngSnsrMultCapb_0_False" 1 "StrgWhlAngSnsrMultCapb_1_True" ;
VAL_ 171 isStrgWhlAngSnsrCalSts 0 "StrgWhlAngSnsrCalSts_0_Unknown" 1 "StrgWhlAngSnsrCalSts_1_Estimated" 2 "StrgWhlAngSnsrCalSts_2_Calibrated" 3 "StrgWhlAngSnsrCalSts_3_Unknown" ;
VAL_ 171 isStrgWhlAng 65535 "StrgWhlAng_65535_error_mark" ;
VAL_ 171 isStrgWhlAngGrd 4095 "StrgWhlAngGrd_4095_error_mark" ;
VAL_ 171 isStrgWhlAngSnsrInid 0 "StrgWhlAngSnsrInid_0_False" 1 "StrgWhlAngSnsrInid_1_True" ;
VAL_ 555 isSysBPM 0 "SysBPM_0_Off" 1 "SysBPM_1_ACC" 2 "SysBPM_2_Run" 3 "SysBPM_3_Crank_Request" ;
VAL_ 555 isSysBPMEnbd 0 "SysBPMEnbd_0_FALSE" 1 "SysBPMEnbd_1_TRUE" ;
VAL_ 474 isLDWLKALVsulznReq 0 "LDWLKALVsulznReq_0_no_display" 1 "LDWLKALVsulznReq_1_line_tracking" 2 "LDWLKALVsulznReq_2_intervention" 3 "LDWLKALVsulznReq_3_warning" 4 "LDWLKALVsulznReq_4_intervention_warning" 5 "LDWLKALVsulznReq_5_Reserved1" 6 "LDWLKALVsulznReq_6_Reserved2" 7 "LDWLKALVsulznReq_7_Reserved3" ;
VAL_ 474 isLDWLKARVsulznReq 0 "LDWLKARVsulznReq_0_no_display" 1 "LDWLKARVsulznReq_1_line_tracking" 2 "LDWLKARVsulznReq_2_intervention" 3 "LDWLKARVsulznReq_3_warning" 4 "LDWLKARVsulznReq_4_intervention_warning" 5 "LDWLKARVsulznReq_5_Reserved1" 6 "LDWLKARVsulznReq_6_Reserved2" 7 "LDWLKARVsulznReq_7_Reserved3" ;
VAL_ 474 isLKASysSts 0 "LKASysSts_0_Off" 1 "LKASysSts_1_Stand_by" 2 "LKASysSts_2_Active" 3 "LKASysSts_3_Override" ;
VAL_ 366 isACCSysSts 0 "ACCSysSts_0_Off" 1 "ACCSysSts_1_Stand_By" 2 "ACCSysSts_2_Active" 3 "ACCSysSts_3_Override" 4 "ACCSysSts_4_Brake_Only" 5 "ACCSysSts_5_Standstill_Active" 6 "ACCSysSts_6_Standstill_Wait" 7 "ACCSysSts_7_Passive" ;
VAL_ 343 isAEBSysSts 0 "AEBSysSts_0_Off" 1 "AEBSysSts_1_On" 2 "AEBSysSts_2_Disable" 3 "AEBSysSts_3_Override" 4 "AEBSysSts_4_Active" 5 "AEBSysSts_5_Reserved1" 6 "AEBSysSts_6_Reserved2" 7 "AEBSysSts_7_Reserved" ;
VAL_ 497 isSysOpnlMd 0 "SysOpnlMd_0_Normal_Mode" 1 "SysOpnlMd_1_Manufacturing_Mode" 2 "SysOpnlMd_2_Transit_Mode" 3 "SysOpnlMd_3_Show_Room" 4 "SysOpnlMd_4_Storage_Mode" 5 "SysOpnlMd_5_Diagnosic_or_Reprogramming_Reserve" 6 "SysOpnlMd_6_Service_mode" ;
VAL_ 497 isSysPwrMd 0 "SysPwrMd_0_Off" 1 "SysPwrMd_1_ACC" 2 "SysPwrMd_2_Run" 3 "SysPwrMd_3_Crank_Request" ;
VAL_ 497 isSysPwrMdV 0 "SysPwrMdV_0_Valid" 1 "SysPwrMdV_1_Invalid" ;
VAL_ 497 isSysVolMd 0 "SysVolMd_0_SysPwrMd_h5_Normal" 1 "SysVolMd_1_Low_System_Voltage" 2 "SysVolMd_2_High_System_Voltage" 3 "SysVolMd_3_Illegal_System_Voltage" ;
VAL_ 497 isSysVolMdV 0 "SysVolMdV_0_Valid" 1 "SysVolMdV_1_Invalid" ;
VAL_ 497 isSysVolV 0 "SysVolV_0_Valid" 1 "SysVolV_1_Invalid" ;
VAL_ 497 isBrkPdlDrvrAppdPrsV 0 "BrkPdlDrvrAppdPrsV_0_Valid" 1 "BrkPdlDrvrAppdPrsV_1_Invalid" ;
VAL_ 497 isBMSAvlbly 0 "BMSAvlbly_0_False" 1 "BMSAvlbly_1_True" ;
VAL_ 497 isSCSAvlbly 0 "SCSAvlbly_0_False" 1 "SCSAvlbly_1_True" ;
VAL_ 497 isVCUAvlbly 0 "VCUAvlbly_0_False" 1 "VCUAvlbly_1_True" ;
VAL_ 497 isIPKAvlbly 0 "IPKAvlbly_0_False" 1 "IPKAvlbly_1_True" ;
VAL_ 497 isFICMAvlbly 0 "FICMAvlbly_0_False" 1 "FICMAvlbly_1_True" ;
VAL_ 497 isBCMAvlbly 0 "BCMAvlbly_0_False" 1 "BCMAvlbly_1_True" ;
VAL_ 497 isSDMAvlbly 0 "SDMAvlbly_0_False" 1 "SDMAvlbly_1_True" ;
VAL_ 497 isADASAvlbly 0 "ADASAvlbly_0_False" 1 "ADASAvlbly_1_True" ;
VAL_ 497 isEPSAvlbly 0 "EPSAvlbly_0_False" 1 "EPSAvlbly_1_True" ;
VAL_ 497 isTCAvlbly 0 "TCAvlbly_0_False" 1 "TCAvlbly_1_True" ;
VAL_ 497 isSASAvlbly 0 "SASAvlbly_0_False" 1 "SASAvlbly_1_True" ;
VAL_ 497 isTBOXAvlbly 0 "TBOXAvlbly_0_False" 1 "TBOXAvlbly_1_True" ;
VAL_ 497 isACAvlbly 0 "ACAvlbly_0_False" 1 "ACAvlbly_1_True" ;
VAL_ 497 isEPBAvlbly 0 "EPBAvlbly_0_False" 1 "EPBAvlbly_1_True" ;
VAL_ 497 isSCUAvlbly 0 "SCUAvlbly_0_False" 1 "SCUAvlbly_1_True" ;
VAL_ 497 isTPMSAvlbly 0 "TPMSAvlbly_0_False" 1 "TPMSAvlbly_1_True" ;
VAL_ 497 isDMSAvlbly 0 "DMSAvlbly_0_False" 1 "DMSAvlbly_1_True" ;
VAL_ 497 isCCUAvlbly 0 "CCUAvlbly_0_False" 1 "CCUAvlbly_1_True" ;
VAL_ 497 isESCLAvlbly 0 "ESCLAvlbly_0_False" 1 "ESCLAvlbly_1_True" ;
VAL_ 497 isRDAAvlbly 0 "RDAAvlbly_0_False" 1 "RDAAvlbly_1_True" ;
VAL_ 497 isPLCMAvlbly 0 "PLCMAvlbly_0_False" 1 "PLCMAvlbly_1_True" ;
VAL_ 497 isTDMAvlbly 0 "TDMAvlbly_0_False" 1 "TDMAvlbly_1_True" ;
VAL_ 497 isRCPDAvlbly 0 "RCPDAvlbly_0_False" 1 "RCPDAvlbly_1_True" ;
VAL_ 1142 isCalendarMonth 0 "CalendarMonth_0_Unknown" 1 "CalendarMonth_1_January" 2 "CalendarMonth_2_February" 3 "CalendarMonth_3_March" 4 "CalendarMonth_4_April" 5 "CalendarMonth_5_May" 6 "CalendarMonth_6_June" 7 "CalendarMonth_7_July" 8 "CalendarMonth_8_August" 9 "CalendarMonth_9_September" 10 "CalendarMonth_10_October" 11 "CalendarMonth_11_November" 12 "CalendarMonth_12_December" ;
VAL_ 1142 isTimeDspFmt 0 "TimeDspFmt_0_12_hour_mode" 1 "TimeDspFmt_1_24_hour_mode" ;
VAL_ 451 isClstrDspdVehSpd 255 "ClstrDspdVehSpd_255_Speed_Signal_Missing_Error_of_SCS" ;
VAL_ 451 isDspMeasSys 0 "DspMeasSys_0_kph" 1 "DspMeasSys_1_mph" ;
VAL_ 814 isVehPwrCsumpMd 0 "VehPwrCsumpMd_0_Normal" 1 "VehPwrCsumpMd_1_Extremely_Low" 2 "VehPwrCsumpMd_2_Low" 3 "VehPwrCsumpMd_3_Reserved" ;
VAL_ 814 isDMSAdoWrnngReq 0 "DMSAdoWrnngReq_0_No_request" 1 "DMSAdoWrnngReq_1_Off" 2 "DMSAdoWrnngReq_2_On" 3 "DMSAdoWrnngReq_3_reserved" ;
VAL_ 814 isDMSHapticWrnngReq 0 "DMSHapticWrnngReq_0_No_request" 1 "DMSHapticWrnngReq_1_Off" 2 "DMSHapticWrnngReq_2_On" 3 "DMSHapticWrnngReq_3_reserved" ;
VAL_ 814 isDMSSwReq 0 "DMSSwReq_0_No_request" 1 "DMSSwReq_1_Off" 2 "DMSSwReq_2_On" 3 "DMSSwReq_3_reserved" ;
VAL_ 814 isFOTASts 0 "FOTASts_0_0_None_FOTA" 1 "FOTASts_1_1_FOTA" ;
VAL_ 814 isFOTAStsV 0 "FOTAStsV_0_0_invalid" 1 "FOTAStsV_1_1_valid" ;
VAL_ 814 isLDircnIndLghtF 0 "LDircnIndLghtF_0_False" 1 "LDircnIndLghtF_1_True" ;
VAL_ 814 isRDircnIndLghtF 0 "RDircnIndLghtF_0_False" 1 "RDircnIndLghtF_1_True" ;
VAL_ 814 isDircnIndLampSwSts 0 "DircnIndLampSwSts_0_Off" 1 "DircnIndLampSwSts_1_Left_On" 2 "DircnIndLampSwSts_2_Right_On" 3 "DircnIndLampSwSts_3_reserve" ;
VAL_ 814 isRstrFctryDeftsReq 0 "RstrFctryDeftsReq_0_False" 1 "RstrFctryDeftsReq_1_True" ;
VAL_ 812 isDrvrDoorOpenSts 0 "DrvrDoorOpenSts_0_Driver_Door_Closed" 1 "DrvrDoorOpenSts_1_Driver_Door_Open_For_latch_switch_can_t_detect_door_ajar_status" 2 "DrvrDoorOpenSts_2_Driver_Door_Ajar" 3 "DrvrDoorOpenSts_3_Driver_Door_Full_Open" ;
VAL_ 165 isBrkPdlAppd 0 "BrkPdlAppd_0_brake_pedal_not_applied" 1 "BrkPdlAppd_1_brake_pedal_applied" ;
VAL_ 165 isBrkPdlAppdV 0 "BrkPdlAppdV_0_Init" 1 "BrkPdlAppdV_1_Normal" 2 "BrkPdlAppdV_2_Faulty" ;
VAL_ 165 isDrvrReqOtptRodTrvlSts 0 "DrvrReqOtptRodTrvlSts_0_Init" 1 "DrvrReqOtptRodTrvlSts_1_Normal" 2 "DrvrReqOtptRodTrvlSts_2_Faulty" ;
VAL_ 318 isVehSpdAvgDrvnV 0 "VehSpdAvgDrvnV_0_Valid" 1 "VehSpdAvgDrvnV_1_Invalid" ;
VAL_ 318 isVehSpdAvgNonDrvnV 0 "VehSpdAvgNonDrvnV_0_Valid" 1 "VehSpdAvgNonDrvnV_1_Invalid" ;
VAL_ 318 isVehSpdAvgV 0 "VehSpdAvgV_0_Valid" 1 "VehSpdAvgV_1_Invalid" ;
VAL_ 318 isDrvrSbltAtc 0 "DrvrSbltAtc_0_False" 1 "DrvrSbltAtc_1_True" ;
VAL_ 318 isDrvrSbltAtcV 0 "DrvrSbltAtcV_0_Valid" 1 "DrvrSbltAtcV_1_Invalid" ;
VAL_ 70 isEPTAccelActuPosV 0 "EPTAccelActuPosV_0_Valid" 1 "EPTAccelActuPosV_1_Invalid" ;
VAL_ 70 isEPTBrkPdlDscrtInptStsV 0 "EPTBrkPdlDscrtInptStsV_0_Valid" 1 "EPTBrkPdlDscrtInptStsV_1_Invalid" ;
VAL_ 70 isEPTBrkPdlDscrtInptSts 0 "EPTBrkPdlDscrtInptSts_0_BrakeNotApplied" 1 "EPTBrkPdlDscrtInptSts_1_BrakeApplied" ;
VAL_ 70 isEPTRdy 0 "EPTRdy_0_NotReady" 1 "EPTRdy_1_Ready" ;
VAL_ 70 isEPTStCmdOn 0 "EPTStCmdOn_0_False" 1 "EPTStCmdOn_1_True" ;
VAL_ 404 isTrShftLvrPosV 0 "TrShftLvrPosV_0_Valid" 1 "TrShftLvrPosV_1_Invalid" ;
VAL_ 404 isTrShftLvrPos 0 "TrShftLvrPos_0_BetweenRanges" 1 "TrShftLvrPos_1_ParkRange" 2 "TrShftLvrPos_2_ReverseRange" 3 "TrShftLvrPos_3_NeutralRange" 4 "TrShftLvrPos_4_ForwardRangeA" 5 "TrShftLvrPos_5_ForwardRangeB" 6 "TrShftLvrPos_6_ForwardRangeC" 7 "TrShftLvrPos_7_ForwardRangeD" 8 "TrShftLvrPos_8_ForwardRangeE" 9 "TrShftLvrPos_9_ForwardRangeF" 10 "TrShftLvrPos_10_ForwardRangeG" 11 "TrShftLvrPos_11_ForwardRangeH" 15 "TrShftLvrPos_15_LeverPositionUnknown" ;
VAL_ 319 isVehDynYawRateV 0 "VehDynYawRateV_0_Valid" 1 "VehDynYawRateV_1_Invalid" ;
VAL_ 319 isVSELatAccV 0 "VSELatAccV_0_ValidET_0_Valid" 1 "VSELatAccV_1_ValidET_1_Invalid" ;
VAL_ 319 isVSELongtAccV 0 "VSELongtAccV_0_Valid" 1 "VSELongtAccV_1_Invalid" ;
VAL_ 1352 isVehOdoV 0 "VehOdoV_0_Valid" 1 "VehOdoV_1_Invalid" ;
VAL_ 924 isDMSDstrctnAdoWrnngReq 0 "DMSDstrctnAdoWrnngReq_0_Norequest" 1 "DMSDstrctnAdoWrnngReq_1_Off" 2 "DMSDstrctnAdoWrnngReq_2_On" 3 "DMSDstrctnAdoWrnngReq_3_reserved" ;
VAL_ 924 isDMSDstrctnHptWrnngReq 0 "DMSDstrctnHptWrnngReq_0_Norequest" 1 "DMSDstrctnHptWrnngReq_1_Off" 2 "DMSDstrctnHptWrnngReq_2_On" 3 "DMSDstrctnHptWrnngReq_3_reserved" ;
VAL_ 924 isDMSDstrctnSwReq 0 "DMSDstrctnSwReq_0_Norequest" 1 "DMSDstrctnSwReq_1_Off" 2 "DMSDstrctnSwReq_2_On" 3 "DMSDstrctnSwReq_3_reserved" ;
VAL_ 192 isDrvrStrgDlvrdToqV 0 "DrvrStrgDlvrdToqV_0_Valid" 1 "DrvrStrgDlvrdToqV_1_Invalid" ;
VAL_ 192 isLDircnIO 0 "LDircnIO_0_False" 1 "LDircnIO_1_True" ;
VAL_ 192 isRDircnIO 0 "RDircnIO_0_False" 1 "RDircnIO_1_True" ;
VAL_ 302 isVSELatAccV_SDM 0 "VSELatAccV_SDM_0_Valid" 1 "VSELatAccV_SDM_1_Invalid" ;
VAL_ 302 isVSELongtAccV_SDM 0 "VSELongtAccV_SDM_0_Valid" 1 "VSELongtAccV_SDM_1_Invalid" ;
VAL_ 302 isVehDynYawRateV_SDM 0 "VehDynYawRateV_SDM_0_Valid" 1 "VehDynYawRateV_SDM_1_Invalid" ;
SIG_GROUP_ 554 DMS_050ms_PDU00 1 : isDMSAdoWrnngDspCmd isDMSAudReq isDMSDspCmd isDMSDstrctnAdoWrnngDspCmd isDMSDstrctnDspCmd isDMSSts isDMSWrnngReq isDrvrAbnormBehvor isDrvrDstcnSts isDrvrFtgLvl isDrvrGazeRgn isDrvrPrst isEyeOnRoad isSpfngDet isDMSDstrctnHptWrnngDspCmd isDMSHapticWrnngDspCmd;
SIG_GROUP_ 171 EPS_010ms_PDU00 1 : isStrgWhlAngSnsrFlt isStrgWhlAngV isStrgWhlAngSnsrMultCapb isStrgWhlAngSnsrCalSts isStrgWhlAng isStrgWhlAngGrd isStrgWhlAngSnsrInid;
SIG_GROUP_ 555 BCM_050ms_PDU40 1 : isSysBPM isSysBPMEnbd;
SIG_GROUP_ 474 FVCM_020ms_PDU01 1 : isLDWLKALVsulznReq isLDWLKARVsulznReq isLKASysSts;
SIG_GROUP_ 366 FDR_020ms_PDU05 1 : isACCSysSts;
SIG_GROUP_ 343 FDR_020ms_PDU06 1 : isAEBSysSts;
SIG_GROUP_ 497 CCP_020ms_PDU02 1 : isSysOpnlMd isSysPwrMd isSysPwrMdV isSysVol isSysVolMd isSysVolMdV isSysVolV;
SIG_GROUP_ 497 SCS_020ms_PDU06 1 : isBrkPdlDrvrAppdPrs isBrkPdlDrvrAppdPrsV;
SIG_GROUP_ 497 CCP_020ms_PDU00 1 : isBMSAvlbly isSCSAvlbly isVCUAvlbly isIPKAvlbly isFICMAvlbly isBCMAvlbly isSDMAvlbly isADASAvlbly isEPSAvlbly isTCAvlbly isSASAvlbly isTBOXAvlbly isACAvlbly isEPBAvlbly isSCUAvlbly isTPMSAvlbly isDMSAvlbly isCCUAvlbly isESCLAvlbly isRDAAvlbly isPLCMAvlbly isTDMAvlbly isRCPDAvlbly;
SIG_GROUP_ 1142 IPK_200ms_PDU06 1 : isCalendarDay isCalendarMonth isCalendarYear isHourOfDay isMinuteOfHour isSecsOfMinute isTimeDspFmt;
SIG_GROUP_ 451 CCP_SigGW_025ms_CANFD_PDU18 1 : isClstrDspdVehSpd isDspMeasSys;
SIG_GROUP_ 814 CCP_100ms_PDU06 1 : isVehPwrCsumpMd;
SIG_GROUP_ 814 FICM_100ms_PDU28 1 : isDMSAdoWrnngReq isDMSHapticWrnngReq isDMSSwReq;
SIG_GROUP_ 814 TBOX_100ms_PDU01 1 : isFOTASts isFOTAStsV;
SIG_GROUP_ 814 CCP_SigGW_100ms_ADCANFD_PDU01 1 : isLDircnIndLghtF isRDircnIndLghtF isDircnIndLampSwSts isRstrFctryDeftsReq;
SIG_GROUP_ 812 BCM_100ms_PDU04 1 : isDrvrDoorOpenSts;
SIG_GROUP_ 165 IBS_010ms_PDU12 1 : isBrkPdlAppd isBrkPdlAppdV isDrvrReqOtptRodTrvl isDrvrReqOtptRodTrvlSts;
SIG_GROUP_ 318 SCS_020ms_PDU15 1 : isVehSpdAvg isVehSpdAvgDrvn isVehSpdAvgDrvnV isVehSpdAvgNonDrvn isVehSpdAvgNonDrvnV isVehSpdAvgV;
SIG_GROUP_ 318 SDM_020ms_PDU00 1 : isDrvrSbltAtc isDrvrSbltAtcV;
SIG_GROUP_ 70 VCU_010ms_PDU00 1 : isEPTAccelActuPos isEPTAccelActuPosV isEPTBrkPdlDscrtInptStsV isEPTBrkPdlDscrtInptSts isEPTRdy isEPTStCmdOn;
SIG_GROUP_ 404 VCU_020ms_PDU10 1 : isTrShftLvrPosV isTrShftLvrPos;
SIG_GROUP_ 319 SCS_020ms_PDU08 1 : isVehDynYawRateV isVehDynYawRate isVSELatAcc isVSELatAccV isVSELongtAcc isVSELongtAccV;
SIG_GROUP_ 1352 CCP_1000ms_PDU14 1 : isVehOdo isVehOdoV;
SIG_GROUP_ 924 FICM_100ms_PDU36 1 : isDMSDstrctnAdoWrnngReq isDMSDstrctnHptWrnngReq isDMSDstrctnSwReq;
SIG_GROUP_ 192 EPS_010ms_PDU07 1 : isDrvrStrgDlvrdToq isDrvrStrgDlvrdToqV;
SIG_GROUP_ 192 CCP_SigGW_010ms_CANFD_PDU17 1 : isLDircnIO isRDircnIO;
SIG_GROUP_ 302 SDM_020ms_PDU08 1 : isVSELatAccV_SDM isVehDynYawRate_SDM isVSELongtAccV_SDM isVSELongtAcc_SDM isVSELatAcc_SDM isVehDynYawRateV_SDM;
